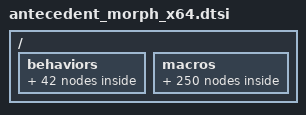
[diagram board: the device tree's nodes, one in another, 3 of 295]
// x64 schema version v1.1
// Automatically generated by Antecedent Morph Configurator

/ {
    behaviors {
        // Mod-Morphs
        // Base layer
        // NE
        amx64neagm: amx64neagm {
            compatible = "zmk,behavior-mod-morph";
            #binding-cells = <0>;
            bindings = <&amx64nea>, <&amx64neg>;
            mods = <(MOD_LGUI)>;
        };
        amx64necagm: amx64necagm {
            compatible = "zmk,behavior-mod-morph";
            #binding-cells = <0>;
            bindings = <&amx64nec>, <&amx64neagm>;
            mods = <(MOD_LALT|MOD_LGUI)>;
        };
        amx64nem: amx64nem {
            compatible = "zmk,behavior-mod-morph";
            #binding-cells = <0>;
            bindings = <&amx64ne>, <&amx64necagm>;
            mods = <(MOD_LCTL|MOD_LALT|MOD_LGUI)>;
        };
        // E
        amx64eagm: amx64eagm {
            compatible = "zmk,behavior-mod-morph";
            #binding-cells = <0>;
            bindings = <&amx64ea>, <&amx64eg>;
            mods = <(MOD_LGUI)>;
        };
        amx64ecagm: amx64ecagm {
            compatible = "zmk,behavior-mod-morph";
            #binding-cells = <0>;
            bindings = <&amx64ec>, <&amx64eagm>;
            mods = <(MOD_LALT|MOD_LGUI)>;
        };
        amx64em: amx64em {
            compatible = "zmk,behavior-mod-morph";
            #binding-cells = <0>;
            bindings = <&amx64e>, <&amx64ecagm>;
            mods = <(MOD_LCTL|MOD_LALT|MOD_LGUI)>;
        };
        // SE
        amx64seagm: amx64seagm {
            compatible = "zmk,behavior-mod-morph";
            #binding-cells = <0>;
            bindings = <&amx64sea>, <&amx64seg>;
            mods = <(MOD_LGUI)>;
        };
        amx64secagm: amx64secagm {
            compatible = "zmk,behavior-mod-morph";
            #binding-cells = <0>;
            bindings = <&amx64sec>, <&amx64seagm>;
            mods = <(MOD_LALT|MOD_LGUI)>;
        };
        amx64sem: amx64sem {
            compatible = "zmk,behavior-mod-morph";
            #binding-cells = <0>;
            bindings = <&amx64se>, <&amx64secagm>;
            mods = <(MOD_LCTL|MOD_LALT|MOD_LGUI)>;
        };
        // NW
        amx64nwagm: amx64nwagm {
            compatible = "zmk,behavior-mod-morph";
            #binding-cells = <0>;
            bindings = <&amx64nwa>, <&amx64nwg>;
            mods = <(MOD_RGUI)>;
        };
        amx64nwcagm: amx64nwcagm {
            compatible = "zmk,behavior-mod-morph";
            #binding-cells = <0>;
            bindings = <&amx64nwc>, <&amx64nwagm>;
            mods = <(MOD_RALT|MOD_RGUI)>;
        };
        amx64nwm: amx64nwm {
            compatible = "zmk,behavior-mod-morph";
            #binding-cells = <0>;
            bindings = <&amx64nw>, <&amx64nwcagm>;
            mods = <(MOD_RCTL|MOD_RALT|MOD_RGUI)>;
        };
        // W
        amx64wagm: amx64wagm {
            compatible = "zmk,behavior-mod-morph";
            #binding-cells = <0>;
            bindings = <&amx64wa>, <&amx64wg>;
            mods = <(MOD_RGUI)>;
        };
        amx64wcagm: amx64wcagm {
            compatible = "zmk,behavior-mod-morph";
            #binding-cells = <0>;
            bindings = <&amx64wc>, <&amx64wagm>;
            mods = <(MOD_RALT|MOD_RGUI)>;
        };
        amx64wm: amx64wm {
            compatible = "zmk,behavior-mod-morph";
            #binding-cells = <0>;
            bindings = <&amx64w>, <&amx64wcagm>;
            mods = <(MOD_RCTL|MOD_RALT|MOD_RGUI)>;
        };
        // SW
        amx64swagm: amx64swagm {
            compatible = "zmk,behavior-mod-morph";
            #binding-cells = <0>;
            bindings = <&amx64swa>, <&amx64swg>;
            mods = <(MOD_RGUI)>;
        };
        amx64swcagm: amx64swcagm {
            compatible = "zmk,behavior-mod-morph";
            #binding-cells = <0>;
            bindings = <&amx64swc>, <&amx64swagm>;
            mods = <(MOD_RALT|MOD_RGUI)>;
        };
        amx64swm: amx64swm {
            compatible = "zmk,behavior-mod-morph";
            #binding-cells = <0>;
            bindings = <&amx64sw>, <&amx64swcagm>;
            mods = <(MOD_RCTL|MOD_RALT|MOD_RGUI)>;
        };
        // Antecedent Morphs
        amx64ne: am_x64_ne {
            compatible = "zmk,behavior-antecedent-morph";
            label = "AM_X64_NE";
            #binding-cells = <0>;
            defaults = <&none>;
            bindings = <&amx64_and>, <&amx64_byte>, <&amx64_cmp>, <&amx64_dword>, <&amx64_rsi_rsi>, <&amx64_ja>, <&amx64_pop>, <&amx64_qword>, <&amx64_repe_cmps>, <&amx64_section>, <&amx64_0123456789>, <&amx64_word>, <&amx64_xor>, <&amx64_ymm0>, <&amx64_ymm1>, <&amx64_ymm2>, <&amx64_ymm3>, <&amx64_ymm4>, <&amx64_ymm5>, <&amx64_ymm6>, <&amx64_ymm7>, <&amx64_ymm8>, <&amx64_ymm9>, <&amx64_macro>;
            antecedents = <A B C D I J P Q R S T W X N0 N1 N2 N3 N4 N5 N6 N7 N8 N9 PRCNT>;
            max-delay-ms = <U_ANTMORPH_DELAY>;
        };
        amx64nec: am_x64_ne_c {
            compatible = "zmk,behavior-antecedent-morph";
            label = "AM_X64_NE_C";
            #binding-cells = <0>;
            defaults = <&none>;
            bindings = <&amx64_cmps>, <&amx64_jae>, <&amx64_repz_cmps>, <&amx64_section_data>, <&amx64_1234567890>, <&amx64_ymm0_ymm0>, <&amx64_ymm1_ymm1>, <&amx64_ymm2_ymm2>, <&amx64_ymm3_ymm3>, <&amx64_ymm4_ymm4>, <&amx64_ymm5_ymm5>, <&amx64_ymm6_ymm6>, <&amx64_ymm7_ymm7>, <&amx64_ymm8_ymm8>, <&amx64_ymm9_ymm9>, <&amx64_unmacro>;
            antecedents = <C J R S T N0 N1 N2 N3 N4 N5 N6 N7 N8 N9 PRCNT>;
            max-delay-ms = <U_ANTMORPH_DELAY>;
        };
        amx64nea: am_x64_ne_a {
            compatible = "zmk,behavior-antecedent-morph";
            label = "AM_X64_NE_A";
            #binding-cells = <0>;
            defaults = <&none>;
            bindings = <&amx64_jna>, <&amx64_repne_cmps>, <&amx64_section_text>;
            antecedents = <J R S>;
            max-delay-ms = <U_ANTMORPH_DELAY>;
        };
        amx64neg: am_x64_ne_g {
            compatible = "zmk,behavior-antecedent-morph";
            label = "AM_X64_NE_G";
            #binding-cells = <0>;
            defaults = <&none>;
            bindings = <&amx64_jnae>, <&amx64_repnz_cmps>, <&amx64_section_bss>, <&amx64_xor_rax_rax>;
            antecedents = <J R S X>;
            max-delay-ms = <U_ANTMORPH_DELAY>;
        };
        amx64e: am_x64_e {
            compatible = "zmk,behavior-antecedent-morph";
            label = "AM_X64_E";
            #binding-cells = <0>;
            defaults = <&none>;
            bindings = <&amx64_add>, <&amx64_bts>, <&amx64_call>, <&amx64_dec>, <&amx64_global>, <&amx64_rdi_rdi>, <&amx64_jmp>, <&amx64_lea>, <&amx64_mul>, <&amx64_push>, <&amx64_rep_stos>, <&amx64_sub>, <&amx64_test>, <&amx64_xorpd>, <&amx64_xmm0>, <&amx64_xmm1>, <&amx64_xmm2>, <&amx64_xmm3>, <&amx64_xmm4>, <&amx64_xmm5>, <&amx64_xmm6>, <&amx64_xmm7>, <&amx64_xmm8>, <&amx64_xmm9>, <&kp MINUS>, <&amx64_define>, <&amx64_rep>, <&amx64_assign>, <&amx64_x64_v11>;
            antecedents = <A B C D G I J L M P R S T X N0 N1 N2 N3 N4 N5 N6 N7 N8 N9 DLLR PRCNT AT EQUAL SPACE>;
            max-delay-ms = <U_ANTMORPH_DELAY>;
        };
        amx64ec: am_x64_e_c {
            compatible = "zmk,behavior-antecedent-morph";
            label = "AM_X64_E_C";
            #binding-cells = <0>;
            defaults = <&none>;
            bindings = <&amx64_addsd>, <&amx64_call_printf>, <&amx64_global_main>, <&amx64_jc>, <&amx64_mulsd>, <&amx64_rep_movs>, <&amx64_subsd>, <&amx64_xorps>, <&amx64_xmm0_xmm0>, <&amx64_xmm1_xmm1>, <&amx64_xmm2_xmm2>, <&amx64_xmm3_xmm3>, <&amx64_xmm4_xmm4>, <&amx64_xmm5_xmm5>, <&amx64_xmm6_xmm6>, <&amx64_xmm7_xmm7>, <&amx64_xmm8_xmm8>, <&amx64_xmm9_xmm9>, <&amx64_undef>, <&amx64_exitrep>;
            antecedents = <A C G J M R S X N0 N1 N2 N3 N4 N5 N6 N7 N8 N9 PRCNT AT>;
            max-delay-ms = <U_ANTMORPH_DELAY>;
        };
        amx64ea: am_x64_e_a {
            compatible = "zmk,behavior-antecedent-morph";
            label = "AM_X64_E_A";
            #binding-cells = <0>;
            defaults = <&none>;
            bindings = <&amx64_addss>, <&amx64_global_start>, <&amx64_jnc>, <&amx64_mulss>, <&amx64_subss>, <&amx64_xdefine>;
            antecedents = <A G J M S PRCNT>;
            max-delay-ms = <U_ANTMORPH_DELAY>;
        };
        amx64eg: am_x64_e_g {
            compatible = "zmk,behavior-antecedent-morph";
            label = "AM_X64_E_G";
            #binding-cells = <0>;
            defaults = <&none>;
            bindings = <&none>;
            antecedents = <0x070100>;
            max-delay-ms = <U_ANTMORPH_DELAY>;
        };
        amx64se: am_x64_se {
            compatible = "zmk,behavior-antecedent-morph";
            label = "AM_X64_SE";
            #binding-cells = <0>;
            defaults = <&none>;
            bindings = <&amx64_btr>, <&amx64_cvtss2sd>, <&amx64_db>, <&amx64_equ>, <&amx64_jb>, <&amx64_movdbu>, <&amx64_pextrb>, <&amx64_resb>, <&amx64_syscall>, <&amx64_0123456789abcde>, <&amx64_vextractf128>, <&amx64_pxor>, <&amx64_00000000>, <&amx64_11111111>, <&amx64_endmacro>, <&amx64_endrep>;
            antecedents = <B C D E J M P R S T V X N0 N1 PRCNT AT>;
            max-delay-ms = <U_ANTMORPH_DELAY>;
        };
        amx64sec: am_x64_se_c {
            compatible = "zmk,behavior-antecedent-morph";
            label = "AM_X64_SE_C";
            #binding-cells = <0>;
            defaults = <&none>;
            bindings = <&amx64_cvtsd2ss>, <&amx64_dw>, <&amx64_equ__>, <&amx64_jbe>, <&amx64_movdwu>, <&amx64_pextrw>, <&amx64_resw>, <&amx64_123456789abcdef>, <&amx64_vextracti128>, <&amx64_000000000000000>, <&amx64_111111111111111>;
            antecedents = <C D E J M P R T V N0 N1>;
            max-delay-ms = <U_ANTMORPH_DELAY>;
        };
        amx64sea: am_x64_se_a {
            compatible = "zmk,behavior-antecedent-morph";
            label = "AM_X64_SE_A";
            #binding-cells = <0>;
            defaults = <&none>;
            bindings = <&amx64_dd>, <&amx64_jnb>, <&amx64_movddu>, <&amx64_pextrd>, <&amx64_resd>, <&amx64_0000000000000001>, <&amx64_1111111111111111>;
            antecedents = <D J M P R N0 N1>;
            max-delay-ms = <U_ANTMORPH_DELAY>;
        };
        amx64seg: am_x64_se_g {
            compatible = "zmk,behavior-antecedent-morph";
            label = "AM_X64_SE_G";
            #binding-cells = <0>;
            defaults = <&none>;
            bindings = <&amx64_dq>, <&amx64_jnbe>, <&amx64_movdqu>, <&amx64_pextrq>, <&amx64_resq>, <&amx64_pxor_xmm0_xmm0>, <&amx64_0000000000000002>, <&amx64_1111111111111112>;
            antecedents = <D J M P R X N0 N1>;
            max-delay-ms = <U_ANTMORPH_DELAY>;
        };
        amx64nw: am_x64_nw {
            compatible = "zmk,behavior-antecedent-morph";
            label = "AM_X64_NW";
            #binding-cells = <0>;
            defaults = <&none>;
            bindings = <&amx64_rax_rax>, <&amx64_rbx_rbx>, <&amx64_rcx_rcx>, <&amx64_rdx_rdx>, <&amx64_extern>, <&amx64_imul>, <&amx64_jg>, <&amx64_loop>, <&amx64_movapd>, <&amx64_not>, <&amx64_or>, <&amx64_rsp_rsp>, <&amx64_repe_scas>, <&amx64_sar>, <&amx64_times>, <&amx64_vmovapd>, <&amx64_r10_r10>, <&amx64_r11_r11>, <&amx64_r12_r12>, <&amx64_r13_r13>, <&amx64_r14_r14>, <&amx64_r15_r15>, <&amx64_r8_r8>, <&amx64_r9_r9>, <&amx64_100>, <&amx64_1001>, <&amx64_include>;
            antecedents = <A B C D E I J L M N O P R S T V N0 N1 N2 N3 N4 N5 N8 N9 COMMA SQT PRCNT>;
            max-delay-ms = <U_ANTMORPH_DELAY>;
        };
        amx64nwc: am_x64_nw_c {
            compatible = "zmk,behavior-antecedent-morph";
            label = "AM_X64_NW_C";
            #binding-cells = <0>;
            defaults = <&none>;
            bindings = <&amx64_extern_printf>, <&amx64_jge>, <&amx64_loop_loop>, <&amx64_movaps>, <&amx64_repz_scas>, <&amx64_shr>, <&amx64_vmovaps>, <&amx64_10100>, <&amx64_101001>;
            antecedents = <E J L M R S V COMMA SQT>;
            max-delay-ms = <U_ANTMORPH_DELAY>;
        };
        amx64nwa: am_x64_nw_a {
            compatible = "zmk,behavior-antecedent-morph";
            label = "AM_X64_NW_A";
            #binding-cells = <0>;
            defaults = <&none>;
            bindings = <&amx64_jng>, <&amx64_movupd>, <&amx64_repne_scas>, <&amx64_vmovupd>;
            antecedents = <J M R V>;
            max-delay-ms = <U_ANTMORPH_DELAY>;
        };
        amx64nwg: am_x64_nw_g {
            compatible = "zmk,behavior-antecedent-morph";
            label = "AM_X64_NW_G";
            #binding-cells = <0>;
            defaults = <&none>;
            bindings = <&amx64_jnge>, <&amx64_movups>, <&amx64_repnz_scas>, <&amx64_vmovups>;
            antecedents = <J M R V>;
            max-delay-ms = <U_ANTMORPH_DELAY>;
        };
        amx64w: am_x64_w {
            compatible = "zmk,behavior-antecedent-morph";
            label = "AM_X64_W";
            #binding-cells = <0>;
            defaults = <&none>;
            bindings = <&amx64_align>, <&amx64_bt>, <&amx64_cpuid>, <&amx64_div>, <&amx64_enter_0_0>, <&amx64_inc>, <&amx64_je>, <&amx64_leave>, <&amx64_mov>, <&amx64_neg>, <&amx64_rbp_rbp>, <&amx64_rol>, <&amx64_sal>, <&amx64_76543210>, <&amx64_vzeroall>, <&amx64_vxorpd>, <&amx64_0xff>, <&kp N0>, <&amx64_0>, <&amx64_if>;
            antecedents = <A B C D E I J L M N P R S T V X N0 COMMA SQT PRCNT>;
            max-delay-ms = <U_ANTMORPH_DELAY>;
        };
        amx64wc: am_x64_w_c {
            compatible = "zmk,behavior-antecedent-morph";
            label = "AM_X64_W_C";
            #binding-cells = <0>;
            defaults = <&none>;
            bindings = <&amx64_alignb>, <&amx64_divsd>, <&amx64_push_rbpmov_rbp>, <&amx64_jz>, <&amx64_mov_rsp_rbppop_>, <&amx64_movsd>, <&amx64_ror>, <&amx64_shl>, <&amx64_1__0>, <&amx64_vxorps>, <&amx64_0xffff>, <&amx64_elif>;
            antecedents = <A D E J L M R S T X N0 PRCNT>;
            max-delay-ms = <U_ANTMORPH_DELAY>;
        };
        amx64wa: am_x64_w_a {
            compatible = "zmk,behavior-antecedent-morph";
            label = "AM_X64_W_A";
            #binding-cells = <0>;
            defaults = <&none>;
            bindings = <&amx64_divss>, <&amx64_jne>, <&amx64_movss>, <&amx64_3__2__1__0>, <&amx64_0xffffffff>, <&amx64_else>;
            antecedents = <D J M T N0 PRCNT>;
            max-delay-ms = <U_ANTMORPH_DELAY>;
        };
        amx64wg: am_x64_w_g {
            compatible = "zmk,behavior-antecedent-morph";
            label = "AM_X64_W_G";
            #binding-cells = <0>;
            defaults = <&none>;
            bindings = <&amx64_jnz>, <&amx64_6__5__4__3__2__>, <&amx64_0xfffffffffffff>;
            antecedents = <J T N0>;
            max-delay-ms = <U_ANTMORPH_DELAY>;
        };
        amx64sw: am_x64_sw {
            compatible = "zmk,behavior-antecedent-morph";
            label = "AM_X64_SW";
            #binding-cells = <0>;
            defaults = <&none>;
            bindings = <&amx64_extractpd>, <&amx64_idiv>, <&amx64_jl>, <&amx64_movdba>, <&amx64_pinsrb>, <&amx64_sqrtsd>, <&amx64_vinsertf128>, <&amx64_0x00>, <&kp N9>, <&amx64_9>, <&amx64_endif>;
            antecedents = <E I J M P S V N0 COMMA SQT PRCNT>;
            max-delay-ms = <U_ANTMORPH_DELAY>;
        };
        amx64swc: am_x64_sw_c {
            compatible = "zmk,behavior-antecedent-morph";
            label = "AM_X64_SW_C";
            #binding-cells = <0>;
            defaults = <&none>;
            bindings = <&amx64_jle>, <&amx64_movdwa>, <&amx64_pinsrw>, <&amx64_vinserti128>, <&amx64_0x0000>;
            antecedents = <J M P V N0>;
            max-delay-ms = <U_ANTMORPH_DELAY>;
        };
        amx64swa: am_x64_sw_a {
            compatible = "zmk,behavior-antecedent-morph";
            label = "AM_X64_SW_A";
            #binding-cells = <0>;
            defaults = <&none>;
            bindings = <&amx64_jnl>, <&amx64_movdda>, <&amx64_pinsrd>, <&amx64_0x00000000>;
            antecedents = <J M P N0>;
            max-delay-ms = <U_ANTMORPH_DELAY>;
        };
        amx64swg: am_x64_sw_g {
            compatible = "zmk,behavior-antecedent-morph";
            label = "AM_X64_SW_G";
            #binding-cells = <0>;
            defaults = <&none>;
            bindings = <&amx64_jnle>, <&amx64_movdqa>, <&amx64_pinsrq>, <&amx64_0x0000000000000>;
            antecedents = <J M P N0>;
            max-delay-ms = <U_ANTMORPH_DELAY>;
        };
    };
    macros {
        // 'A'
        amx64_and: amx64_and {
            compatible = "zmk,behavior-macro";
            #binding-cells = <0>;
            wait-ms = <U_ANTMORPH_MACRO_WAIT>;
            tap-ms = <U_ANTMORPH_MACRO_TAP>;
            // (a)nd     
            bindings = <&macro_tap &kp N &kp D &kp SPACE &kp SPACE &kp SPACE &kp SPACE &kp SPACE>;
        };
        amx64_add: amx64_add {
            compatible = "zmk,behavior-macro";
            #binding-cells = <0>;
            wait-ms = <U_ANTMORPH_MACRO_WAIT>;
            tap-ms = <U_ANTMORPH_MACRO_TAP>;
            // (a)dd     
            bindings = <&macro_tap &kp D &kp D &kp SPACE &kp SPACE &kp SPACE &kp SPACE &kp SPACE>;
        };
        amx64_addsd: amx64_addsd {
            compatible = "zmk,behavior-macro";
            #binding-cells = <0>;
            wait-ms = <U_ANTMORPH_MACRO_WAIT>;
            tap-ms = <U_ANTMORPH_MACRO_TAP>;
            // (a)ddsd   
            bindings = <&macro_release &kp LCTRL>, <&macro_tap &kp D &kp D &kp S &kp D &kp SPACE &kp SPACE &kp SPACE>;
        };
        amx64_addss: amx64_addss {
            compatible = "zmk,behavior-macro";
            #binding-cells = <0>;
            wait-ms = <U_ANTMORPH_MACRO_WAIT>;
            tap-ms = <U_ANTMORPH_MACRO_TAP>;
            // (a)ddss   
            bindings = <&macro_release &kp LALT>, <&macro_tap &kp LALT>, <&macro_tap &kp D &kp D &kp S &kp S &kp SPACE &kp SPACE &kp SPACE>;
        };
        amx64_rax_rax: amx64_rax_rax {
            compatible = "zmk,behavior-macro";
            #binding-cells = <0>;
            wait-ms = <U_ANTMORPH_MACRO_WAIT>;
            tap-ms = <U_ANTMORPH_MACRO_TAP>;
            // [a]rax, rax
            bindings = <&macro_tap &kp BSPC &kp R &kp A &kp X &kp COMMA &kp SPACE &kp R &kp A &kp X>;
        };
        amx64_align: amx64_align {
            compatible = "zmk,behavior-macro";
            #binding-cells = <0>;
            wait-ms = <U_ANTMORPH_MACRO_WAIT>;
            tap-ms = <U_ANTMORPH_MACRO_TAP>;
            // (a)lign 
            bindings = <&macro_tap &kp L &kp I &kp G &kp N &kp SPACE>;
        };
        amx64_alignb: amx64_alignb {
            compatible = "zmk,behavior-macro";
            #binding-cells = <0>;
            wait-ms = <U_ANTMORPH_MACRO_WAIT>;
            tap-ms = <U_ANTMORPH_MACRO_TAP>;
            // (a)lignb 
            bindings = <&macro_release &kp RCTRL>, <&macro_tap &kp L &kp I &kp G &kp N &kp B &kp SPACE>;
        };
        // 'B'
        amx64_byte: amx64_byte {
            compatible = "zmk,behavior-macro";
            #binding-cells = <0>;
            wait-ms = <U_ANTMORPH_MACRO_WAIT>;
            tap-ms = <U_ANTMORPH_MACRO_TAP>;
            // (b)yte
            bindings = <&macro_tap &kp Y &kp T &kp E>;
        };
        amx64_bts: amx64_bts {
            compatible = "zmk,behavior-macro";
            #binding-cells = <0>;
            wait-ms = <U_ANTMORPH_MACRO_WAIT>;
            tap-ms = <U_ANTMORPH_MACRO_TAP>;
            // (b)ts     
            bindings = <&macro_tap &kp T &kp S &kp SPACE &kp SPACE &kp SPACE &kp SPACE &kp SPACE>;
        };
        amx64_btr: amx64_btr {
            compatible = "zmk,behavior-macro";
            #binding-cells = <0>;
            wait-ms = <U_ANTMORPH_MACRO_WAIT>;
            tap-ms = <U_ANTMORPH_MACRO_TAP>;
            // (b)tr     
            bindings = <&macro_tap &kp T &kp R &kp SPACE &kp SPACE &kp SPACE &kp SPACE &kp SPACE>;
        };
        amx64_rbx_rbx: amx64_rbx_rbx {
            compatible = "zmk,behavior-macro";
            #binding-cells = <0>;
            wait-ms = <U_ANTMORPH_MACRO_WAIT>;
            tap-ms = <U_ANTMORPH_MACRO_TAP>;
            // [b]rbx, rbx
            bindings = <&macro_tap &kp BSPC &kp R &kp B &kp X &kp COMMA &kp SPACE &kp R &kp B &kp X>;
        };
        amx64_bt: amx64_bt {
            compatible = "zmk,behavior-macro";
            #binding-cells = <0>;
            wait-ms = <U_ANTMORPH_MACRO_WAIT>;
            tap-ms = <U_ANTMORPH_MACRO_TAP>;
            // (b)t      
            bindings = <&macro_tap &kp T &kp SPACE &kp SPACE &kp SPACE &kp SPACE &kp SPACE &kp SPACE>;
        };
        // 'C'
        amx64_cmp: amx64_cmp {
            compatible = "zmk,behavior-macro";
            #binding-cells = <0>;
            wait-ms = <U_ANTMORPH_MACRO_WAIT>;
            tap-ms = <U_ANTMORPH_MACRO_TAP>;
            // (c)mp     
            bindings = <&macro_tap &kp M &kp P &kp SPACE &kp SPACE &kp SPACE &kp SPACE &kp SPACE>;
        };
        amx64_cmps: amx64_cmps {
            compatible = "zmk,behavior-macro";
            #binding-cells = <0>;
            wait-ms = <U_ANTMORPH_MACRO_WAIT>;
            tap-ms = <U_ANTMORPH_MACRO_TAP>;
            // (c)mps
            bindings = <&macro_release &kp LCTRL>, <&macro_tap &kp M &kp P &kp S>;
        };
        amx64_call: amx64_call {
            compatible = "zmk,behavior-macro";
            #binding-cells = <0>;
            wait-ms = <U_ANTMORPH_MACRO_WAIT>;
            tap-ms = <U_ANTMORPH_MACRO_TAP>;
            // (c)all    
            bindings = <&macro_tap &kp A &kp L &kp L &kp SPACE &kp SPACE &kp SPACE &kp SPACE>;
        };
        amx64_call_printf: amx64_call_printf {
            compatible = "zmk,behavior-macro";
            #binding-cells = <0>;
            wait-ms = <U_ANTMORPH_MACRO_WAIT>;
            tap-ms = <U_ANTMORPH_MACRO_TAP>;
            // (c)all    printf
            bindings = <&macro_release &kp LCTRL>, <&macro_tap &kp A &kp L &kp L &kp SPACE &kp SPACE &kp SPACE &kp SPACE &kp P &kp R &kp I &kp N &kp T &kp F>;
        };
        amx64_cvtss2sd: amx64_cvtss2sd {
            compatible = "zmk,behavior-macro";
            #binding-cells = <0>;
            wait-ms = <U_ANTMORPH_MACRO_WAIT>;
            tap-ms = <U_ANTMORPH_MACRO_TAP>;
            // (c)vtss2sd 
            bindings = <&macro_tap &kp V &kp T &kp S &kp S &kp N2 &kp S &kp D &kp SPACE>;
        };
        amx64_cvtsd2ss: amx64_cvtsd2ss {
            compatible = "zmk,behavior-macro";
            #binding-cells = <0>;
            wait-ms = <U_ANTMORPH_MACRO_WAIT>;
            tap-ms = <U_ANTMORPH_MACRO_TAP>;
            // (c)vtsd2ss 
            bindings = <&macro_release &kp LCTRL>, <&macro_tap &kp V &kp T &kp S &kp D &kp N2 &kp S &kp S &kp SPACE>;
        };
        amx64_rcx_rcx: amx64_rcx_rcx {
            compatible = "zmk,behavior-macro";
            #binding-cells = <0>;
            wait-ms = <U_ANTMORPH_MACRO_WAIT>;
            tap-ms = <U_ANTMORPH_MACRO_TAP>;
            // [c]rcx, rcx
            bindings = <&macro_tap &kp BSPC &kp R &kp C &kp X &kp COMMA &kp SPACE &kp R &kp C &kp X>;
        };
        amx64_cpuid: amx64_cpuid {
            compatible = "zmk,behavior-macro";
            #binding-cells = <0>;
            wait-ms = <U_ANTMORPH_MACRO_WAIT>;
            tap-ms = <U_ANTMORPH_MACRO_TAP>;
            // (c)puid
            bindings = <&macro_tap &kp P &kp U &kp I &kp D>;
        };
        // 'D'
        amx64_dword: amx64_dword {
            compatible = "zmk,behavior-macro";
            #binding-cells = <0>;
            wait-ms = <U_ANTMORPH_MACRO_WAIT>;
            tap-ms = <U_ANTMORPH_MACRO_TAP>;
            // (d)word
            bindings = <&macro_tap &kp W &kp O &kp R &kp D>;
        };
        amx64_dec: amx64_dec {
            compatible = "zmk,behavior-macro";
            #binding-cells = <0>;
            wait-ms = <U_ANTMORPH_MACRO_WAIT>;
            tap-ms = <U_ANTMORPH_MACRO_TAP>;
            // (d)ec     
            bindings = <&macro_tap &kp E &kp C &kp SPACE &kp SPACE &kp SPACE &kp SPACE &kp SPACE>;
        };
        amx64_db: amx64_db {
            compatible = "zmk,behavior-macro";
            #binding-cells = <0>;
            wait-ms = <U_ANTMORPH_MACRO_WAIT>;
            tap-ms = <U_ANTMORPH_MACRO_TAP>;
            // (d)b   
            bindings = <&macro_tap &kp B &kp SPACE &kp SPACE &kp SPACE>;
        };
        amx64_dw: amx64_dw {
            compatible = "zmk,behavior-macro";
            #binding-cells = <0>;
            wait-ms = <U_ANTMORPH_MACRO_WAIT>;
            tap-ms = <U_ANTMORPH_MACRO_TAP>;
            // (d)w   
            bindings = <&macro_release &kp LCTRL>, <&macro_tap &kp W &kp SPACE &kp SPACE &kp SPACE>;
        };
        amx64_dd: amx64_dd {
            compatible = "zmk,behavior-macro";
            #binding-cells = <0>;
            wait-ms = <U_ANTMORPH_MACRO_WAIT>;
            tap-ms = <U_ANTMORPH_MACRO_TAP>;
            // (d)d   
            bindings = <&macro_release &kp LALT>, <&macro_tap &kp LALT>, <&macro_tap &kp D &kp SPACE &kp SPACE &kp SPACE>;
        };
        amx64_dq: amx64_dq {
            compatible = "zmk,behavior-macro";
            #binding-cells = <0>;
            wait-ms = <U_ANTMORPH_MACRO_WAIT>;
            tap-ms = <U_ANTMORPH_MACRO_TAP>;
            // (d)q   
            bindings = <&macro_release &kp LGUI>, <&macro_tap &kp LGUI>, <&macro_tap &kp Q &kp SPACE &kp SPACE &kp SPACE>;
        };
        amx64_rdx_rdx: amx64_rdx_rdx {
            compatible = "zmk,behavior-macro";
            #binding-cells = <0>;
            wait-ms = <U_ANTMORPH_MACRO_WAIT>;
            tap-ms = <U_ANTMORPH_MACRO_TAP>;
            // [d]rdx, rdx
            bindings = <&macro_tap &kp BSPC &kp R &kp D &kp X &kp COMMA &kp SPACE &kp R &kp D &kp X>;
        };
        amx64_div: amx64_div {
            compatible = "zmk,behavior-macro";
            #binding-cells = <0>;
            wait-ms = <U_ANTMORPH_MACRO_WAIT>;
            tap-ms = <U_ANTMORPH_MACRO_TAP>;
            // (d)iv     
            bindings = <&macro_tap &kp I &kp V &kp SPACE &kp SPACE &kp SPACE &kp SPACE &kp SPACE>;
        };
        amx64_divsd: amx64_divsd {
            compatible = "zmk,behavior-macro";
            #binding-cells = <0>;
            wait-ms = <U_ANTMORPH_MACRO_WAIT>;
            tap-ms = <U_ANTMORPH_MACRO_TAP>;
            // (d)ivsd   
            bindings = <&macro_release &kp RCTRL>, <&macro_tap &kp I &kp V &kp S &kp D &kp SPACE &kp SPACE &kp SPACE>;
        };
        amx64_divss: amx64_divss {
            compatible = "zmk,behavior-macro";
            #binding-cells = <0>;
            wait-ms = <U_ANTMORPH_MACRO_WAIT>;
            tap-ms = <U_ANTMORPH_MACRO_TAP>;
            // (d)ivss   
            bindings = <&macro_release &kp RALT>, <&macro_tap &kp RALT>, <&macro_tap &kp I &kp V &kp S &kp S &kp SPACE &kp SPACE &kp SPACE>;
        };
        // 'E'
        amx64_equ: amx64_equ {
            compatible = "zmk,behavior-macro";
            #binding-cells = <0>;
            wait-ms = <U_ANTMORPH_MACRO_WAIT>;
            tap-ms = <U_ANTMORPH_MACRO_TAP>;
            // (e)qu  
            bindings = <&macro_tap &kp Q &kp U &kp SPACE &kp SPACE>;
        };
        amx64_equ__: amx64_equ__ {
            compatible = "zmk,behavior-macro";
            #binding-cells = <0>;
            wait-ms = <U_ANTMORPH_MACRO_WAIT>;
            tap-ms = <U_ANTMORPH_MACRO_TAP>;
            // (e)qu  $-
            bindings = <&macro_release &kp LCTRL>, <&macro_tap &kp Q &kp U &kp SPACE &kp SPACE &kp DLLR &kp MINUS>;
        };
        amx64_extern: amx64_extern {
            compatible = "zmk,behavior-macro";
            #binding-cells = <0>;
            wait-ms = <U_ANTMORPH_MACRO_WAIT>;
            tap-ms = <U_ANTMORPH_MACRO_TAP>;
            // (e)xtern 
            bindings = <&macro_tap &kp X &kp T &kp E &kp R &kp N &kp SPACE>;
        };
        amx64_extern_printf: amx64_extern_printf {
            compatible = "zmk,behavior-macro";
            #binding-cells = <0>;
            wait-ms = <U_ANTMORPH_MACRO_WAIT>;
            tap-ms = <U_ANTMORPH_MACRO_TAP>;
            // (e)xtern printf
            bindings = <&macro_release &kp RCTRL>, <&macro_tap &kp X &kp T &kp E &kp R &kp N &kp SPACE &kp P &kp R &kp I &kp N &kp T &kp F>;
        };
        amx64_enter_0_0: amx64_enter_0_0 {
            compatible = "zmk,behavior-macro";
            #binding-cells = <0>;
            wait-ms = <U_ANTMORPH_MACRO_WAIT>;
            tap-ms = <U_ANTMORPH_MACRO_TAP>;
            // (e)nter   0, 0
            bindings = <&macro_tap &kp N &kp T &kp E &kp R &kp SPACE &kp SPACE &kp SPACE &kp N0 &kp COMMA &kp SPACE &kp N0>;
        };
        amx64_push_rbpmov_rbp: amx64_push_rbpmov_rbp {
            compatible = "zmk,behavior-macro";
            #binding-cells = <0>;
            wait-ms = <U_ANTMORPH_MACRO_WAIT>;
            tap-ms = <U_ANTMORPH_MACRO_TAP>;
            // [e]push    rbp⏎mov     rbp, rsp
            bindings = <&macro_release &kp RCTRL>, <&macro_tap &kp BSPC &kp P &kp U &kp S &kp H &kp SPACE &kp SPACE &kp SPACE &kp SPACE &kp R &kp B &kp P &kp RET &kp M &kp O &kp V &kp SPACE &kp SPACE &kp SPACE &kp SPACE &kp SPACE &kp R &kp B &kp P &kp COMMA &kp SPACE &kp R &kp S &kp P>;
        };
        amx64_extractpd: amx64_extractpd {
            compatible = "zmk,behavior-macro";
            #binding-cells = <0>;
            wait-ms = <U_ANTMORPH_MACRO_WAIT>;
            tap-ms = <U_ANTMORPH_MACRO_TAP>;
            // (e)xtractpd 
            bindings = <&macro_tap &kp X &kp T &kp R &kp A &kp C &kp T &kp P &kp D &kp SPACE>;
        };
        // 'G'
        amx64_global: amx64_global {
            compatible = "zmk,behavior-macro";
            #binding-cells = <0>;
            wait-ms = <U_ANTMORPH_MACRO_WAIT>;
            tap-ms = <U_ANTMORPH_MACRO_TAP>;
            // (g)lobal 
            bindings = <&macro_tap &kp L &kp O &kp B &kp A &kp L &kp SPACE>;
        };
        amx64_global_main: amx64_global_main {
            compatible = "zmk,behavior-macro";
            #binding-cells = <0>;
            wait-ms = <U_ANTMORPH_MACRO_WAIT>;
            tap-ms = <U_ANTMORPH_MACRO_TAP>;
            // (g)lobal main
            bindings = <&macro_release &kp LCTRL>, <&macro_tap &kp L &kp O &kp B &kp A &kp L &kp SPACE &kp M &kp A &kp I &kp N>;
        };
        amx64_global_start: amx64_global_start {
            compatible = "zmk,behavior-macro";
            #binding-cells = <0>;
            wait-ms = <U_ANTMORPH_MACRO_WAIT>;
            tap-ms = <U_ANTMORPH_MACRO_TAP>;
            // (g)lobal _start
            bindings = <&macro_release &kp LALT>, <&macro_tap &kp LALT>, <&macro_tap &kp L &kp O &kp B &kp A &kp L &kp SPACE &kp UNDER &kp S &kp T &kp A &kp R &kp T>;
        };
        // 'I'
        amx64_rsi_rsi: amx64_rsi_rsi {
            compatible = "zmk,behavior-macro";
            #binding-cells = <0>;
            wait-ms = <U_ANTMORPH_MACRO_WAIT>;
            tap-ms = <U_ANTMORPH_MACRO_TAP>;
            // [i]rsi, rsi
            bindings = <&macro_tap &kp BSPC &kp R &kp S &kp I &kp COMMA &kp SPACE &kp R &kp S &kp I>;
        };
        amx64_rdi_rdi: amx64_rdi_rdi {
            compatible = "zmk,behavior-macro";
            #binding-cells = <0>;
            wait-ms = <U_ANTMORPH_MACRO_WAIT>;
            tap-ms = <U_ANTMORPH_MACRO_TAP>;
            // [i]rdi, rdi
            bindings = <&macro_tap &kp BSPC &kp R &kp D &kp I &kp COMMA &kp SPACE &kp R &kp D &kp I>;
        };
        amx64_imul: amx64_imul {
            compatible = "zmk,behavior-macro";
            #binding-cells = <0>;
            wait-ms = <U_ANTMORPH_MACRO_WAIT>;
            tap-ms = <U_ANTMORPH_MACRO_TAP>;
            // (i)mul    
            bindings = <&macro_tap &kp M &kp U &kp L &kp SPACE &kp SPACE &kp SPACE &kp SPACE>;
        };
        amx64_inc: amx64_inc {
            compatible = "zmk,behavior-macro";
            #binding-cells = <0>;
            wait-ms = <U_ANTMORPH_MACRO_WAIT>;
            tap-ms = <U_ANTMORPH_MACRO_TAP>;
            // (i)nc     
            bindings = <&macro_tap &kp N &kp C &kp SPACE &kp SPACE &kp SPACE &kp SPACE &kp SPACE>;
        };
        amx64_idiv: amx64_idiv {
            compatible = "zmk,behavior-macro";
            #binding-cells = <0>;
            wait-ms = <U_ANTMORPH_MACRO_WAIT>;
            tap-ms = <U_ANTMORPH_MACRO_TAP>;
            // (i)div    
            bindings = <&macro_tap &kp D &kp I &kp V &kp SPACE &kp SPACE &kp SPACE &kp SPACE>;
        };
        // 'J'
        amx64_ja: amx64_ja {
            compatible = "zmk,behavior-macro";
            #binding-cells = <0>;
            wait-ms = <U_ANTMORPH_MACRO_WAIT>;
            tap-ms = <U_ANTMORPH_MACRO_TAP>;
            // (j)a      
            bindings = <&macro_tap &kp A &kp SPACE &kp SPACE &kp SPACE &kp SPACE &kp SPACE &kp SPACE>;
        };
        amx64_jae: amx64_jae {
            compatible = "zmk,behavior-macro";
            #binding-cells = <0>;
            wait-ms = <U_ANTMORPH_MACRO_WAIT>;
            tap-ms = <U_ANTMORPH_MACRO_TAP>;
            // (j)ae     
            bindings = <&macro_release &kp LCTRL>, <&macro_tap &kp A &kp E &kp SPACE &kp SPACE &kp SPACE &kp SPACE &kp SPACE>;
        };
        amx64_jna: amx64_jna {
            compatible = "zmk,behavior-macro";
            #binding-cells = <0>;
            wait-ms = <U_ANTMORPH_MACRO_WAIT>;
            tap-ms = <U_ANTMORPH_MACRO_TAP>;
            // (j)na     
            bindings = <&macro_release &kp LALT>, <&macro_tap &kp LALT>, <&macro_tap &kp N &kp A &kp SPACE &kp SPACE &kp SPACE &kp SPACE &kp SPACE>;
        };
        amx64_jnae: amx64_jnae {
            compatible = "zmk,behavior-macro";
            #binding-cells = <0>;
            wait-ms = <U_ANTMORPH_MACRO_WAIT>;
            tap-ms = <U_ANTMORPH_MACRO_TAP>;
            // (j)nae    
            bindings = <&macro_release &kp LGUI>, <&macro_tap &kp LGUI>, <&macro_tap &kp N &kp A &kp E &kp SPACE &kp SPACE &kp SPACE &kp SPACE>;
        };
        amx64_jmp: amx64_jmp {
            compatible = "zmk,behavior-macro";
            #binding-cells = <0>;
            wait-ms = <U_ANTMORPH_MACRO_WAIT>;
            tap-ms = <U_ANTMORPH_MACRO_TAP>;
            // (j)mp     
            bindings = <&macro_tap &kp M &kp P &kp SPACE &kp SPACE &kp SPACE &kp SPACE &kp SPACE>;
        };
        amx64_jc: amx64_jc {
            compatible = "zmk,behavior-macro";
            #binding-cells = <0>;
            wait-ms = <U_ANTMORPH_MACRO_WAIT>;
            tap-ms = <U_ANTMORPH_MACRO_TAP>;
            // (j)c      
            bindings = <&macro_release &kp LCTRL>, <&macro_tap &kp C &kp SPACE &kp SPACE &kp SPACE &kp SPACE &kp SPACE &kp SPACE>;
        };
        amx64_jnc: amx64_jnc {
            compatible = "zmk,behavior-macro";
            #binding-cells = <0>;
            wait-ms = <U_ANTMORPH_MACRO_WAIT>;
            tap-ms = <U_ANTMORPH_MACRO_TAP>;
            // (j)nc     
            bindings = <&macro_release &kp LALT>, <&macro_tap &kp LALT>, <&macro_tap &kp N &kp C &kp SPACE &kp SPACE &kp SPACE &kp SPACE &kp SPACE>;
        };
        amx64_jb: amx64_jb {
            compatible = "zmk,behavior-macro";
            #binding-cells = <0>;
            wait-ms = <U_ANTMORPH_MACRO_WAIT>;
            tap-ms = <U_ANTMORPH_MACRO_TAP>;
            // (j)b      
            bindings = <&macro_tap &kp B &kp SPACE &kp SPACE &kp SPACE &kp SPACE &kp SPACE &kp SPACE>;
        };
        amx64_jbe: amx64_jbe {
            compatible = "zmk,behavior-macro";
            #binding-cells = <0>;
            wait-ms = <U_ANTMORPH_MACRO_WAIT>;
            tap-ms = <U_ANTMORPH_MACRO_TAP>;
            // (j)be     
            bindings = <&macro_release &kp LCTRL>, <&macro_tap &kp B &kp E &kp SPACE &kp SPACE &kp SPACE &kp SPACE &kp SPACE>;
        };
        amx64_jnb: amx64_jnb {
            compatible = "zmk,behavior-macro";
            #binding-cells = <0>;
            wait-ms = <U_ANTMORPH_MACRO_WAIT>;
            tap-ms = <U_ANTMORPH_MACRO_TAP>;
            // (j)nb     
            bindings = <&macro_release &kp LALT>, <&macro_tap &kp LALT>, <&macro_tap &kp N &kp B &kp SPACE &kp SPACE &kp SPACE &kp SPACE &kp SPACE>;
        };
        amx64_jnbe: amx64_jnbe {
            compatible = "zmk,behavior-macro";
            #binding-cells = <0>;
            wait-ms = <U_ANTMORPH_MACRO_WAIT>;
            tap-ms = <U_ANTMORPH_MACRO_TAP>;
            // (j)nbe    
            bindings = <&macro_release &kp LGUI>, <&macro_tap &kp LGUI>, <&macro_tap &kp N &kp B &kp E &kp SPACE &kp SPACE &kp SPACE &kp SPACE>;
        };
        amx64_jg: amx64_jg {
            compatible = "zmk,behavior-macro";
            #binding-cells = <0>;
            wait-ms = <U_ANTMORPH_MACRO_WAIT>;
            tap-ms = <U_ANTMORPH_MACRO_TAP>;
            // (j)g      
            bindings = <&macro_tap &kp G &kp SPACE &kp SPACE &kp SPACE &kp SPACE &kp SPACE &kp SPACE>;
        };
        amx64_jge: amx64_jge {
            compatible = "zmk,behavior-macro";
            #binding-cells = <0>;
            wait-ms = <U_ANTMORPH_MACRO_WAIT>;
            tap-ms = <U_ANTMORPH_MACRO_TAP>;
            // (j)ge     
            bindings = <&macro_release &kp RCTRL>, <&macro_tap &kp G &kp E &kp SPACE &kp SPACE &kp SPACE &kp SPACE &kp SPACE>;
        };
        amx64_jng: amx64_jng {
            compatible = "zmk,behavior-macro";
            #binding-cells = <0>;
            wait-ms = <U_ANTMORPH_MACRO_WAIT>;
            tap-ms = <U_ANTMORPH_MACRO_TAP>;
            // (j)ng     
            bindings = <&macro_release &kp RALT>, <&macro_tap &kp RALT>, <&macro_tap &kp N &kp G &kp SPACE &kp SPACE &kp SPACE &kp SPACE &kp SPACE>;
        };
        amx64_jnge: amx64_jnge {
            compatible = "zmk,behavior-macro";
            #binding-cells = <0>;
            wait-ms = <U_ANTMORPH_MACRO_WAIT>;
            tap-ms = <U_ANTMORPH_MACRO_TAP>;
            // (j)nge    
            bindings = <&macro_release &kp RGUI>, <&macro_tap &kp RGUI>, <&macro_tap &kp N &kp G &kp E &kp SPACE &kp SPACE &kp SPACE &kp SPACE>;
        };
        amx64_je: amx64_je {
            compatible = "zmk,behavior-macro";
            #binding-cells = <0>;
            wait-ms = <U_ANTMORPH_MACRO_WAIT>;
            tap-ms = <U_ANTMORPH_MACRO_TAP>;
            // (j)e      
            bindings = <&macro_tap &kp E &kp SPACE &kp SPACE &kp SPACE &kp SPACE &kp SPACE &kp SPACE>;
        };
        amx64_jz: amx64_jz {
            compatible = "zmk,behavior-macro";
            #binding-cells = <0>;
            wait-ms = <U_ANTMORPH_MACRO_WAIT>;
            tap-ms = <U_ANTMORPH_MACRO_TAP>;
            // (j)z      
            bindings = <&macro_release &kp RCTRL>, <&macro_tap &kp Z &kp SPACE &kp SPACE &kp SPACE &kp SPACE &kp SPACE &kp SPACE>;
        };
        amx64_jne: amx64_jne {
            compatible = "zmk,behavior-macro";
            #binding-cells = <0>;
            wait-ms = <U_ANTMORPH_MACRO_WAIT>;
            tap-ms = <U_ANTMORPH_MACRO_TAP>;
            // (j)ne     
            bindings = <&macro_release &kp RALT>, <&macro_tap &kp RALT>, <&macro_tap &kp N &kp E &kp SPACE &kp SPACE &kp SPACE &kp SPACE &kp SPACE>;
        };
        amx64_jnz: amx64_jnz {
            compatible = "zmk,behavior-macro";
            #binding-cells = <0>;
            wait-ms = <U_ANTMORPH_MACRO_WAIT>;
            tap-ms = <U_ANTMORPH_MACRO_TAP>;
            // (j)nz     
            bindings = <&macro_release &kp RGUI>, <&macro_tap &kp RGUI>, <&macro_tap &kp N &kp Z &kp SPACE &kp SPACE &kp SPACE &kp SPACE &kp SPACE>;
        };
        amx64_jl: amx64_jl {
            compatible = "zmk,behavior-macro";
            #binding-cells = <0>;
            wait-ms = <U_ANTMORPH_MACRO_WAIT>;
            tap-ms = <U_ANTMORPH_MACRO_TAP>;
            // (j)l      
            bindings = <&macro_tap &kp L &kp SPACE &kp SPACE &kp SPACE &kp SPACE &kp SPACE &kp SPACE>;
        };
        amx64_jle: amx64_jle {
            compatible = "zmk,behavior-macro";
            #binding-cells = <0>;
            wait-ms = <U_ANTMORPH_MACRO_WAIT>;
            tap-ms = <U_ANTMORPH_MACRO_TAP>;
            // (j)le     
            bindings = <&macro_release &kp RCTRL>, <&macro_tap &kp L &kp E &kp SPACE &kp SPACE &kp SPACE &kp SPACE &kp SPACE>;
        };
        amx64_jnl: amx64_jnl {
            compatible = "zmk,behavior-macro";
            #binding-cells = <0>;
            wait-ms = <U_ANTMORPH_MACRO_WAIT>;
            tap-ms = <U_ANTMORPH_MACRO_TAP>;
            // (j)nl     
            bindings = <&macro_release &kp RALT>, <&macro_tap &kp RALT>, <&macro_tap &kp N &kp L &kp SPACE &kp SPACE &kp SPACE &kp SPACE &kp SPACE>;
        };
        amx64_jnle: amx64_jnle {
            compatible = "zmk,behavior-macro";
            #binding-cells = <0>;
            wait-ms = <U_ANTMORPH_MACRO_WAIT>;
            tap-ms = <U_ANTMORPH_MACRO_TAP>;
            // (j)nle    
            bindings = <&macro_release &kp RGUI>, <&macro_tap &kp RGUI>, <&macro_tap &kp N &kp L &kp E &kp SPACE &kp SPACE &kp SPACE &kp SPACE>;
        };
        // 'L'
        amx64_lea: amx64_lea {
            compatible = "zmk,behavior-macro";
            #binding-cells = <0>;
            wait-ms = <U_ANTMORPH_MACRO_WAIT>;
            tap-ms = <U_ANTMORPH_MACRO_TAP>;
            // (l)ea     
            bindings = <&macro_tap &kp E &kp A &kp SPACE &kp SPACE &kp SPACE &kp SPACE &kp SPACE>;
        };
        amx64_loop: amx64_loop {
            compatible = "zmk,behavior-macro";
            #binding-cells = <0>;
            wait-ms = <U_ANTMORPH_MACRO_WAIT>;
            tap-ms = <U_ANTMORPH_MACRO_TAP>;
            // (l)oop    
            bindings = <&macro_tap &kp O &kp O &kp P &kp SPACE &kp SPACE &kp SPACE &kp SPACE>;
        };
        amx64_loop_loop: amx64_loop_loop {
            compatible = "zmk,behavior-macro";
            #binding-cells = <0>;
            wait-ms = <U_ANTMORPH_MACRO_WAIT>;
            tap-ms = <U_ANTMORPH_MACRO_TAP>;
            // (l)oop    .loop
            bindings = <&macro_release &kp RCTRL>, <&macro_tap &kp O &kp O &kp P &kp SPACE &kp SPACE &kp SPACE &kp SPACE &kp DOT &kp L &kp O &kp O &kp P>;
        };
        amx64_leave: amx64_leave {
            compatible = "zmk,behavior-macro";
            #binding-cells = <0>;
            wait-ms = <U_ANTMORPH_MACRO_WAIT>;
            tap-ms = <U_ANTMORPH_MACRO_TAP>;
            // (l)eave
            bindings = <&macro_tap &kp E &kp A &kp V &kp E>;
        };
        amx64_mov_rsp_rbppop_: amx64_mov_rsp_rbppop_ {
            compatible = "zmk,behavior-macro";
            #binding-cells = <0>;
            wait-ms = <U_ANTMORPH_MACRO_WAIT>;
            tap-ms = <U_ANTMORPH_MACRO_TAP>;
            // [l]mov     rsp, rbp⏎pop     rbp
            bindings = <&macro_release &kp RCTRL>, <&macro_tap &kp BSPC &kp M &kp O &kp V &kp SPACE &kp SPACE &kp SPACE &kp SPACE &kp SPACE &kp R &kp S &kp P &kp COMMA &kp SPACE &kp R &kp B &kp P &kp RET &kp P &kp O &kp P &kp SPACE &kp SPACE &kp SPACE &kp SPACE &kp SPACE &kp R &kp B &kp P>;
        };
        // 'M'
        amx64_mul: amx64_mul {
            compatible = "zmk,behavior-macro";
            #binding-cells = <0>;
            wait-ms = <U_ANTMORPH_MACRO_WAIT>;
            tap-ms = <U_ANTMORPH_MACRO_TAP>;
            // (m)ul     
            bindings = <&macro_tap &kp U &kp L &kp SPACE &kp SPACE &kp SPACE &kp SPACE &kp SPACE>;
        };
        amx64_mulsd: amx64_mulsd {
            compatible = "zmk,behavior-macro";
            #binding-cells = <0>;
            wait-ms = <U_ANTMORPH_MACRO_WAIT>;
            tap-ms = <U_ANTMORPH_MACRO_TAP>;
            // (m)ulsd   
            bindings = <&macro_release &kp LCTRL>, <&macro_tap &kp U &kp L &kp S &kp D &kp SPACE &kp SPACE &kp SPACE>;
        };
        amx64_mulss: amx64_mulss {
            compatible = "zmk,behavior-macro";
            #binding-cells = <0>;
            wait-ms = <U_ANTMORPH_MACRO_WAIT>;
            tap-ms = <U_ANTMORPH_MACRO_TAP>;
            // (m)ulss   
            bindings = <&macro_release &kp LALT>, <&macro_tap &kp LALT>, <&macro_tap &kp U &kp L &kp S &kp S &kp SPACE &kp SPACE &kp SPACE>;
        };
        amx64_movdbu: amx64_movdbu {
            compatible = "zmk,behavior-macro";
            #binding-cells = <0>;
            wait-ms = <U_ANTMORPH_MACRO_WAIT>;
            tap-ms = <U_ANTMORPH_MACRO_TAP>;
            // (m)ovdbu  
            bindings = <&macro_tap &kp O &kp V &kp D &kp B &kp U &kp SPACE &kp SPACE>;
        };
        amx64_movdwu: amx64_movdwu {
            compatible = "zmk,behavior-macro";
            #binding-cells = <0>;
            wait-ms = <U_ANTMORPH_MACRO_WAIT>;
            tap-ms = <U_ANTMORPH_MACRO_TAP>;
            // (m)ovdwu  
            bindings = <&macro_release &kp LCTRL>, <&macro_tap &kp O &kp V &kp D &kp W &kp U &kp SPACE &kp SPACE>;
        };
        amx64_movddu: amx64_movddu {
            compatible = "zmk,behavior-macro";
            #binding-cells = <0>;
            wait-ms = <U_ANTMORPH_MACRO_WAIT>;
            tap-ms = <U_ANTMORPH_MACRO_TAP>;
            // (m)ovddu  
            bindings = <&macro_release &kp LALT>, <&macro_tap &kp LALT>, <&macro_tap &kp O &kp V &kp D &kp D &kp U &kp SPACE &kp SPACE>;
        };
        amx64_movdqu: amx64_movdqu {
            compatible = "zmk,behavior-macro";
            #binding-cells = <0>;
            wait-ms = <U_ANTMORPH_MACRO_WAIT>;
            tap-ms = <U_ANTMORPH_MACRO_TAP>;
            // (m)ovdqu  
            bindings = <&macro_release &kp LGUI>, <&macro_tap &kp LGUI>, <&macro_tap &kp O &kp V &kp D &kp Q &kp U &kp SPACE &kp SPACE>;
        };
        amx64_movapd: amx64_movapd {
            compatible = "zmk,behavior-macro";
            #binding-cells = <0>;
            wait-ms = <U_ANTMORPH_MACRO_WAIT>;
            tap-ms = <U_ANTMORPH_MACRO_TAP>;
            // (m)ovapd  
            bindings = <&macro_tap &kp O &kp V &kp A &kp P &kp D &kp SPACE &kp SPACE>;
        };
        amx64_movaps: amx64_movaps {
            compatible = "zmk,behavior-macro";
            #binding-cells = <0>;
            wait-ms = <U_ANTMORPH_MACRO_WAIT>;
            tap-ms = <U_ANTMORPH_MACRO_TAP>;
            // (m)ovaps  
            bindings = <&macro_release &kp RCTRL>, <&macro_tap &kp O &kp V &kp A &kp P &kp S &kp SPACE &kp SPACE>;
        };
        amx64_movupd: amx64_movupd {
            compatible = "zmk,behavior-macro";
            #binding-cells = <0>;
            wait-ms = <U_ANTMORPH_MACRO_WAIT>;
            tap-ms = <U_ANTMORPH_MACRO_TAP>;
            // (m)ovupd  
            bindings = <&macro_release &kp RALT>, <&macro_tap &kp RALT>, <&macro_tap &kp O &kp V &kp U &kp P &kp D &kp SPACE &kp SPACE>;
        };
        amx64_movups: amx64_movups {
            compatible = "zmk,behavior-macro";
            #binding-cells = <0>;
            wait-ms = <U_ANTMORPH_MACRO_WAIT>;
            tap-ms = <U_ANTMORPH_MACRO_TAP>;
            // (m)ovups  
            bindings = <&macro_release &kp RGUI>, <&macro_tap &kp RGUI>, <&macro_tap &kp O &kp V &kp U &kp P &kp S &kp SPACE &kp SPACE>;
        };
        amx64_mov: amx64_mov {
            compatible = "zmk,behavior-macro";
            #binding-cells = <0>;
            wait-ms = <U_ANTMORPH_MACRO_WAIT>;
            tap-ms = <U_ANTMORPH_MACRO_TAP>;
            // (m)ov     
            bindings = <&macro_tap &kp O &kp V &kp SPACE &kp SPACE &kp SPACE &kp SPACE &kp SPACE>;
        };
        amx64_movsd: amx64_movsd {
            compatible = "zmk,behavior-macro";
            #binding-cells = <0>;
            wait-ms = <U_ANTMORPH_MACRO_WAIT>;
            tap-ms = <U_ANTMORPH_MACRO_TAP>;
            // (m)ovsd   
            bindings = <&macro_release &kp RCTRL>, <&macro_tap &kp O &kp V &kp S &kp D &kp SPACE &kp SPACE &kp SPACE>;
        };
        amx64_movss: amx64_movss {
            compatible = "zmk,behavior-macro";
            #binding-cells = <0>;
            wait-ms = <U_ANTMORPH_MACRO_WAIT>;
            tap-ms = <U_ANTMORPH_MACRO_TAP>;
            // (m)ovss   
            bindings = <&macro_release &kp RALT>, <&macro_tap &kp RALT>, <&macro_tap &kp O &kp V &kp S &kp S &kp SPACE &kp SPACE &kp SPACE>;
        };
        amx64_movdba: amx64_movdba {
            compatible = "zmk,behavior-macro";
            #binding-cells = <0>;
            wait-ms = <U_ANTMORPH_MACRO_WAIT>;
            tap-ms = <U_ANTMORPH_MACRO_TAP>;
            // (m)ovdba  
            bindings = <&macro_tap &kp O &kp V &kp D &kp B &kp A &kp SPACE &kp SPACE>;
        };
        amx64_movdwa: amx64_movdwa {
            compatible = "zmk,behavior-macro";
            #binding-cells = <0>;
            wait-ms = <U_ANTMORPH_MACRO_WAIT>;
            tap-ms = <U_ANTMORPH_MACRO_TAP>;
            // (m)ovdwa  
            bindings = <&macro_release &kp RCTRL>, <&macro_tap &kp O &kp V &kp D &kp W &kp A &kp SPACE &kp SPACE>;
        };
        amx64_movdda: amx64_movdda {
            compatible = "zmk,behavior-macro";
            #binding-cells = <0>;
            wait-ms = <U_ANTMORPH_MACRO_WAIT>;
            tap-ms = <U_ANTMORPH_MACRO_TAP>;
            // (m)ovdda  
            bindings = <&macro_release &kp RALT>, <&macro_tap &kp RALT>, <&macro_tap &kp O &kp V &kp D &kp D &kp A &kp SPACE &kp SPACE>;
        };
        amx64_movdqa: amx64_movdqa {
            compatible = "zmk,behavior-macro";
            #binding-cells = <0>;
            wait-ms = <U_ANTMORPH_MACRO_WAIT>;
            tap-ms = <U_ANTMORPH_MACRO_TAP>;
            // (m)ovdqa  
            bindings = <&macro_release &kp RGUI>, <&macro_tap &kp RGUI>, <&macro_tap &kp O &kp V &kp D &kp Q &kp A &kp SPACE &kp SPACE>;
        };
        // 'N'
        amx64_not: amx64_not {
            compatible = "zmk,behavior-macro";
            #binding-cells = <0>;
            wait-ms = <U_ANTMORPH_MACRO_WAIT>;
            tap-ms = <U_ANTMORPH_MACRO_TAP>;
            // (n)ot     
            bindings = <&macro_tap &kp O &kp T &kp SPACE &kp SPACE &kp SPACE &kp SPACE &kp SPACE>;
        };
        amx64_neg: amx64_neg {
            compatible = "zmk,behavior-macro";
            #binding-cells = <0>;
            wait-ms = <U_ANTMORPH_MACRO_WAIT>;
            tap-ms = <U_ANTMORPH_MACRO_TAP>;
            // (n)eg      
            bindings = <&macro_tap &kp E &kp G &kp SPACE &kp SPACE &kp SPACE &kp SPACE &kp SPACE &kp SPACE>;
        };
        // 'O'
        amx64_or: amx64_or {
            compatible = "zmk,behavior-macro";
            #binding-cells = <0>;
            wait-ms = <U_ANTMORPH_MACRO_WAIT>;
            tap-ms = <U_ANTMORPH_MACRO_TAP>;
            // (o)r      
            bindings = <&macro_tap &kp R &kp SPACE &kp SPACE &kp SPACE &kp SPACE &kp SPACE &kp SPACE>;
        };
        // 'P'
        amx64_pop: amx64_pop {
            compatible = "zmk,behavior-macro";
            #binding-cells = <0>;
            wait-ms = <U_ANTMORPH_MACRO_WAIT>;
            tap-ms = <U_ANTMORPH_MACRO_TAP>;
            // (p)op     
            bindings = <&macro_tap &kp O &kp P &kp SPACE &kp SPACE &kp SPACE &kp SPACE &kp SPACE>;
        };
        amx64_push: amx64_push {
            compatible = "zmk,behavior-macro";
            #binding-cells = <0>;
            wait-ms = <U_ANTMORPH_MACRO_WAIT>;
            tap-ms = <U_ANTMORPH_MACRO_TAP>;
            // (p)ush    
            bindings = <&macro_tap &kp U &kp S &kp H &kp SPACE &kp SPACE &kp SPACE &kp SPACE>;
        };
        amx64_pextrb: amx64_pextrb {
            compatible = "zmk,behavior-macro";
            #binding-cells = <0>;
            wait-ms = <U_ANTMORPH_MACRO_WAIT>;
            tap-ms = <U_ANTMORPH_MACRO_TAP>;
            // (p)extrb  
            bindings = <&macro_tap &kp E &kp X &kp T &kp R &kp B &kp SPACE &kp SPACE>;
        };
        amx64_pextrw: amx64_pextrw {
            compatible = "zmk,behavior-macro";
            #binding-cells = <0>;
            wait-ms = <U_ANTMORPH_MACRO_WAIT>;
            tap-ms = <U_ANTMORPH_MACRO_TAP>;
            // (p)extrw  
            bindings = <&macro_release &kp LCTRL>, <&macro_tap &kp E &kp X &kp T &kp R &kp W &kp SPACE &kp SPACE>;
        };
        amx64_pextrd: amx64_pextrd {
            compatible = "zmk,behavior-macro";
            #binding-cells = <0>;
            wait-ms = <U_ANTMORPH_MACRO_WAIT>;
            tap-ms = <U_ANTMORPH_MACRO_TAP>;
            // (p)extrd  
            bindings = <&macro_release &kp LALT>, <&macro_tap &kp LALT>, <&macro_tap &kp E &kp X &kp T &kp R &kp D &kp SPACE &kp SPACE>;
        };
        amx64_pextrq: amx64_pextrq {
            compatible = "zmk,behavior-macro";
            #binding-cells = <0>;
            wait-ms = <U_ANTMORPH_MACRO_WAIT>;
            tap-ms = <U_ANTMORPH_MACRO_TAP>;
            // (p)extrq  
            bindings = <&macro_release &kp LGUI>, <&macro_tap &kp LGUI>, <&macro_tap &kp E &kp X &kp T &kp R &kp Q &kp SPACE &kp SPACE>;
        };
        amx64_rsp_rsp: amx64_rsp_rsp {
            compatible = "zmk,behavior-macro";
            #binding-cells = <0>;
            wait-ms = <U_ANTMORPH_MACRO_WAIT>;
            tap-ms = <U_ANTMORPH_MACRO_TAP>;
            // [p]rsp, rsp
            bindings = <&macro_tap &kp BSPC &kp R &kp S &kp P &kp COMMA &kp SPACE &kp R &kp S &kp P>;
        };
        amx64_rbp_rbp: amx64_rbp_rbp {
            compatible = "zmk,behavior-macro";
            #binding-cells = <0>;
            wait-ms = <U_ANTMORPH_MACRO_WAIT>;
            tap-ms = <U_ANTMORPH_MACRO_TAP>;
            // [p]rbp, rbp
            bindings = <&macro_tap &kp BSPC &kp R &kp B &kp P &kp COMMA &kp SPACE &kp R &kp B &kp P>;
        };
        amx64_pinsrb: amx64_pinsrb {
            compatible = "zmk,behavior-macro";
            #binding-cells = <0>;
            wait-ms = <U_ANTMORPH_MACRO_WAIT>;
            tap-ms = <U_ANTMORPH_MACRO_TAP>;
            // (p)insrb  
            bindings = <&macro_tap &kp I &kp N &kp S &kp R &kp B &kp SPACE &kp SPACE>;
        };
        amx64_pinsrw: amx64_pinsrw {
            compatible = "zmk,behavior-macro";
            #binding-cells = <0>;
            wait-ms = <U_ANTMORPH_MACRO_WAIT>;
            tap-ms = <U_ANTMORPH_MACRO_TAP>;
            // (p)insrw  
            bindings = <&macro_release &kp RCTRL>, <&macro_tap &kp I &kp N &kp S &kp R &kp W &kp SPACE &kp SPACE>;
        };
        amx64_pinsrd: amx64_pinsrd {
            compatible = "zmk,behavior-macro";
            #binding-cells = <0>;
            wait-ms = <U_ANTMORPH_MACRO_WAIT>;
            tap-ms = <U_ANTMORPH_MACRO_TAP>;
            // (p)insrd  
            bindings = <&macro_release &kp RALT>, <&macro_tap &kp RALT>, <&macro_tap &kp I &kp N &kp S &kp R &kp D &kp SPACE &kp SPACE>;
        };
        amx64_pinsrq: amx64_pinsrq {
            compatible = "zmk,behavior-macro";
            #binding-cells = <0>;
            wait-ms = <U_ANTMORPH_MACRO_WAIT>;
            tap-ms = <U_ANTMORPH_MACRO_TAP>;
            // (p)insrq  
            bindings = <&macro_release &kp RGUI>, <&macro_tap &kp RGUI>, <&macro_tap &kp I &kp N &kp S &kp R &kp Q &kp SPACE &kp SPACE>;
        };
        // 'Q'
        amx64_qword: amx64_qword {
            compatible = "zmk,behavior-macro";
            #binding-cells = <0>;
            wait-ms = <U_ANTMORPH_MACRO_WAIT>;
            tap-ms = <U_ANTMORPH_MACRO_TAP>;
            // (q)word
            bindings = <&macro_tap &kp W &kp O &kp R &kp D>;
        };
        // 'R'
        amx64_repe_cmps: amx64_repe_cmps {
            compatible = "zmk,behavior-macro";
            #binding-cells = <0>;
            wait-ms = <U_ANTMORPH_MACRO_WAIT>;
            tap-ms = <U_ANTMORPH_MACRO_TAP>;
            // (r)epe cmps
            bindings = <&macro_tap &kp E &kp P &kp E &kp SPACE &kp C &kp M &kp P &kp S>;
        };
        amx64_repz_cmps: amx64_repz_cmps {
            compatible = "zmk,behavior-macro";
            #binding-cells = <0>;
            wait-ms = <U_ANTMORPH_MACRO_WAIT>;
            tap-ms = <U_ANTMORPH_MACRO_TAP>;
            // (r)epz cmps
            bindings = <&macro_release &kp LCTRL>, <&macro_tap &kp E &kp P &kp Z &kp SPACE &kp C &kp M &kp P &kp S>;
        };
        amx64_repne_cmps: amx64_repne_cmps {
            compatible = "zmk,behavior-macro";
            #binding-cells = <0>;
            wait-ms = <U_ANTMORPH_MACRO_WAIT>;
            tap-ms = <U_ANTMORPH_MACRO_TAP>;
            // (r)epne cmps
            bindings = <&macro_release &kp LALT>, <&macro_tap &kp LALT>, <&macro_tap &kp E &kp P &kp N &kp E &kp SPACE &kp C &kp M &kp P &kp S>;
        };
        amx64_repnz_cmps: amx64_repnz_cmps {
            compatible = "zmk,behavior-macro";
            #binding-cells = <0>;
            wait-ms = <U_ANTMORPH_MACRO_WAIT>;
            tap-ms = <U_ANTMORPH_MACRO_TAP>;
            // (r)epnz cmps
            bindings = <&macro_release &kp LGUI>, <&macro_tap &kp LGUI>, <&macro_tap &kp E &kp P &kp N &kp Z &kp SPACE &kp C &kp M &kp P &kp S>;
        };
        amx64_rep_stos: amx64_rep_stos {
            compatible = "zmk,behavior-macro";
            #binding-cells = <0>;
            wait-ms = <U_ANTMORPH_MACRO_WAIT>;
            tap-ms = <U_ANTMORPH_MACRO_TAP>;
            // (r)ep stos
            bindings = <&macro_tap &kp E &kp P &kp SPACE &kp S &kp T &kp O &kp S>;
        };
        amx64_rep_movs: amx64_rep_movs {
            compatible = "zmk,behavior-macro";
            #binding-cells = <0>;
            wait-ms = <U_ANTMORPH_MACRO_WAIT>;
            tap-ms = <U_ANTMORPH_MACRO_TAP>;
            // (r)ep movs
            bindings = <&macro_release &kp LCTRL>, <&macro_tap &kp E &kp P &kp SPACE &kp M &kp O &kp V &kp S>;
        };
        amx64_resb: amx64_resb {
            compatible = "zmk,behavior-macro";
            #binding-cells = <0>;
            wait-ms = <U_ANTMORPH_MACRO_WAIT>;
            tap-ms = <U_ANTMORPH_MACRO_TAP>;
            // (r)esb 
            bindings = <&macro_tap &kp E &kp S &kp B &kp SPACE>;
        };
        amx64_resw: amx64_resw {
            compatible = "zmk,behavior-macro";
            #binding-cells = <0>;
            wait-ms = <U_ANTMORPH_MACRO_WAIT>;
            tap-ms = <U_ANTMORPH_MACRO_TAP>;
            // (r)esw 
            bindings = <&macro_release &kp LCTRL>, <&macro_tap &kp E &kp S &kp W &kp SPACE>;
        };
        amx64_resd: amx64_resd {
            compatible = "zmk,behavior-macro";
            #binding-cells = <0>;
            wait-ms = <U_ANTMORPH_MACRO_WAIT>;
            tap-ms = <U_ANTMORPH_MACRO_TAP>;
            // (r)esd 
            bindings = <&macro_release &kp LALT>, <&macro_tap &kp LALT>, <&macro_tap &kp E &kp S &kp D &kp SPACE>;
        };
        amx64_resq: amx64_resq {
            compatible = "zmk,behavior-macro";
            #binding-cells = <0>;
            wait-ms = <U_ANTMORPH_MACRO_WAIT>;
            tap-ms = <U_ANTMORPH_MACRO_TAP>;
            // (r)esq 
            bindings = <&macro_release &kp LGUI>, <&macro_tap &kp LGUI>, <&macro_tap &kp E &kp S &kp Q &kp SPACE>;
        };
        amx64_repe_scas: amx64_repe_scas {
            compatible = "zmk,behavior-macro";
            #binding-cells = <0>;
            wait-ms = <U_ANTMORPH_MACRO_WAIT>;
            tap-ms = <U_ANTMORPH_MACRO_TAP>;
            // (r)epe scas
            bindings = <&macro_tap &kp E &kp P &kp E &kp SPACE &kp S &kp C &kp A &kp S>;
        };
        amx64_repz_scas: amx64_repz_scas {
            compatible = "zmk,behavior-macro";
            #binding-cells = <0>;
            wait-ms = <U_ANTMORPH_MACRO_WAIT>;
            tap-ms = <U_ANTMORPH_MACRO_TAP>;
            // (r)epz scas
            bindings = <&macro_release &kp RCTRL>, <&macro_tap &kp E &kp P &kp Z &kp SPACE &kp S &kp C &kp A &kp S>;
        };
        amx64_repne_scas: amx64_repne_scas {
            compatible = "zmk,behavior-macro";
            #binding-cells = <0>;
            wait-ms = <U_ANTMORPH_MACRO_WAIT>;
            tap-ms = <U_ANTMORPH_MACRO_TAP>;
            // (r)epne scas
            bindings = <&macro_release &kp RALT>, <&macro_tap &kp RALT>, <&macro_tap &kp E &kp P &kp N &kp E &kp SPACE &kp S &kp C &kp A &kp S>;
        };
        amx64_repnz_scas: amx64_repnz_scas {
            compatible = "zmk,behavior-macro";
            #binding-cells = <0>;
            wait-ms = <U_ANTMORPH_MACRO_WAIT>;
            tap-ms = <U_ANTMORPH_MACRO_TAP>;
            // (r)epnz scas
            bindings = <&macro_release &kp RGUI>, <&macro_tap &kp RGUI>, <&macro_tap &kp E &kp P &kp N &kp Z &kp SPACE &kp S &kp C &kp A &kp S>;
        };
        amx64_rol: amx64_rol {
            compatible = "zmk,behavior-macro";
            #binding-cells = <0>;
            wait-ms = <U_ANTMORPH_MACRO_WAIT>;
            tap-ms = <U_ANTMORPH_MACRO_TAP>;
            // (r)ol     
            bindings = <&macro_tap &kp O &kp L &kp SPACE &kp SPACE &kp SPACE &kp SPACE &kp SPACE>;
        };
        amx64_ror: amx64_ror {
            compatible = "zmk,behavior-macro";
            #binding-cells = <0>;
            wait-ms = <U_ANTMORPH_MACRO_WAIT>;
            tap-ms = <U_ANTMORPH_MACRO_TAP>;
            // (r)or     
            bindings = <&macro_release &kp RCTRL>, <&macro_tap &kp O &kp R &kp SPACE &kp SPACE &kp SPACE &kp SPACE &kp SPACE>;
        };
        // 'S'
        amx64_section: amx64_section {
            compatible = "zmk,behavior-macro";
            #binding-cells = <0>;
            wait-ms = <U_ANTMORPH_MACRO_WAIT>;
            tap-ms = <U_ANTMORPH_MACRO_TAP>;
            // (s)ection 
            bindings = <&macro_tap &kp E &kp C &kp T &kp I &kp O &kp N &kp SPACE>;
        };
        amx64_section_data: amx64_section_data {
            compatible = "zmk,behavior-macro";
            #binding-cells = <0>;
            wait-ms = <U_ANTMORPH_MACRO_WAIT>;
            tap-ms = <U_ANTMORPH_MACRO_TAP>;
            // (s)ection .data
            bindings = <&macro_release &kp LCTRL>, <&macro_tap &kp E &kp C &kp T &kp I &kp O &kp N &kp SPACE &kp DOT &kp D &kp A &kp T &kp A>;
        };
        amx64_section_text: amx64_section_text {
            compatible = "zmk,behavior-macro";
            #binding-cells = <0>;
            wait-ms = <U_ANTMORPH_MACRO_WAIT>;
            tap-ms = <U_ANTMORPH_MACRO_TAP>;
            // (s)ection .text
            bindings = <&macro_release &kp LALT>, <&macro_tap &kp LALT>, <&macro_tap &kp E &kp C &kp T &kp I &kp O &kp N &kp SPACE &kp DOT &kp T &kp E &kp X &kp T>;
        };
        amx64_section_bss: amx64_section_bss {
            compatible = "zmk,behavior-macro";
            #binding-cells = <0>;
            wait-ms = <U_ANTMORPH_MACRO_WAIT>;
            tap-ms = <U_ANTMORPH_MACRO_TAP>;
            // (s)ection .bss
            bindings = <&macro_release &kp LGUI>, <&macro_tap &kp LGUI>, <&macro_tap &kp E &kp C &kp T &kp I &kp O &kp N &kp SPACE &kp DOT &kp B &kp S &kp S>;
        };
        amx64_sub: amx64_sub {
            compatible = "zmk,behavior-macro";
            #binding-cells = <0>;
            wait-ms = <U_ANTMORPH_MACRO_WAIT>;
            tap-ms = <U_ANTMORPH_MACRO_TAP>;
            // (s)ub     
            bindings = <&macro_tap &kp U &kp B &kp SPACE &kp SPACE &kp SPACE &kp SPACE &kp SPACE>;
        };
        amx64_subsd: amx64_subsd {
            compatible = "zmk,behavior-macro";
            #binding-cells = <0>;
            wait-ms = <U_ANTMORPH_MACRO_WAIT>;
            tap-ms = <U_ANTMORPH_MACRO_TAP>;
            // (s)ubsd   
            bindings = <&macro_release &kp LCTRL>, <&macro_tap &kp U &kp B &kp S &kp D &kp SPACE &kp SPACE &kp SPACE>;
        };
        amx64_subss: amx64_subss {
            compatible = "zmk,behavior-macro";
            #binding-cells = <0>;
            wait-ms = <U_ANTMORPH_MACRO_WAIT>;
            tap-ms = <U_ANTMORPH_MACRO_TAP>;
            // (s)ubss   
            bindings = <&macro_release &kp LALT>, <&macro_tap &kp LALT>, <&macro_tap &kp U &kp B &kp S &kp S &kp SPACE &kp SPACE &kp SPACE>;
        };
        amx64_syscall: amx64_syscall {
            compatible = "zmk,behavior-macro";
            #binding-cells = <0>;
            wait-ms = <U_ANTMORPH_MACRO_WAIT>;
            tap-ms = <U_ANTMORPH_MACRO_TAP>;
            // (s)yscall
            bindings = <&macro_tap &kp Y &kp S &kp C &kp A &kp L &kp L>;
        };
        amx64_sar: amx64_sar {
            compatible = "zmk,behavior-macro";
            #binding-cells = <0>;
            wait-ms = <U_ANTMORPH_MACRO_WAIT>;
            tap-ms = <U_ANTMORPH_MACRO_TAP>;
            // (s)ar     
            bindings = <&macro_tap &kp A &kp R &kp SPACE &kp SPACE &kp SPACE &kp SPACE &kp SPACE>;
        };
        amx64_shr: amx64_shr {
            compatible = "zmk,behavior-macro";
            #binding-cells = <0>;
            wait-ms = <U_ANTMORPH_MACRO_WAIT>;
            tap-ms = <U_ANTMORPH_MACRO_TAP>;
            // (s)hr     
            bindings = <&macro_release &kp RCTRL>, <&macro_tap &kp H &kp R &kp SPACE &kp SPACE &kp SPACE &kp SPACE &kp SPACE>;
        };
        amx64_sal: amx64_sal {
            compatible = "zmk,behavior-macro";
            #binding-cells = <0>;
            wait-ms = <U_ANTMORPH_MACRO_WAIT>;
            tap-ms = <U_ANTMORPH_MACRO_TAP>;
            // (s)al     
            bindings = <&macro_tap &kp A &kp L &kp SPACE &kp SPACE &kp SPACE &kp SPACE &kp SPACE>;
        };
        amx64_shl: amx64_shl {
            compatible = "zmk,behavior-macro";
            #binding-cells = <0>;
            wait-ms = <U_ANTMORPH_MACRO_WAIT>;
            tap-ms = <U_ANTMORPH_MACRO_TAP>;
            // (s)hl     
            bindings = <&macro_release &kp RCTRL>, <&macro_tap &kp H &kp L &kp SPACE &kp SPACE &kp SPACE &kp SPACE &kp SPACE>;
        };
        amx64_sqrtsd: amx64_sqrtsd {
            compatible = "zmk,behavior-macro";
            #binding-cells = <0>;
            wait-ms = <U_ANTMORPH_MACRO_WAIT>;
            tap-ms = <U_ANTMORPH_MACRO_TAP>;
            // (s)qrtsd  
            bindings = <&macro_tap &kp Q &kp R &kp T &kp S &kp D &kp SPACE &kp SPACE>;
        };
        // 'T'
        amx64_0123456789: amx64_0123456789 {
            compatible = "zmk,behavior-macro";
            #binding-cells = <0>;
            wait-ms = <U_ANTMORPH_MACRO_WAIT>;
            tap-ms = <U_ANTMORPH_MACRO_TAP>;
            // [t]0123456789
            bindings = <&macro_tap &kp BSPC &kp N0 &kp N1 &kp N2 &kp N3 &kp N4 &kp N5 &kp N6 &kp N7 &kp N8 &kp N9>;
        };
        amx64_1234567890: amx64_1234567890 {
            compatible = "zmk,behavior-macro";
            #binding-cells = <0>;
            wait-ms = <U_ANTMORPH_MACRO_WAIT>;
            tap-ms = <U_ANTMORPH_MACRO_TAP>;
            // [t]1234567890
            bindings = <&macro_release &kp LCTRL>, <&macro_tap &kp BSPC &kp N1 &kp N2 &kp N3 &kp N4 &kp N5 &kp N6 &kp N7 &kp N8 &kp N9 &kp N0>;
        };
        amx64_test: amx64_test {
            compatible = "zmk,behavior-macro";
            #binding-cells = <0>;
            wait-ms = <U_ANTMORPH_MACRO_WAIT>;
            tap-ms = <U_ANTMORPH_MACRO_TAP>;
            // (t)est    
            bindings = <&macro_tap &kp E &kp S &kp T &kp SPACE &kp SPACE &kp SPACE &kp SPACE>;
        };
        amx64_0123456789abcde: amx64_0123456789abcde {
            compatible = "zmk,behavior-macro";
            #binding-cells = <0>;
            wait-ms = <U_ANTMORPH_MACRO_WAIT>;
            tap-ms = <U_ANTMORPH_MACRO_TAP>;
            // [t]0123456789abcdef
            bindings = <&macro_tap &kp BSPC &kp N0 &kp N1 &kp N2 &kp N3 &kp N4 &kp N5 &kp N6 &kp N7 &kp N8 &kp N9 &kp A &kp B &kp C &kp D &kp E &kp F>;
        };
        amx64_123456789abcdef: amx64_123456789abcdef {
            compatible = "zmk,behavior-macro";
            #binding-cells = <0>;
            wait-ms = <U_ANTMORPH_MACRO_WAIT>;
            tap-ms = <U_ANTMORPH_MACRO_TAP>;
            // [t]123456789abcdef0
            bindings = <&macro_release &kp LCTRL>, <&macro_tap &kp BSPC &kp N1 &kp N2 &kp N3 &kp N4 &kp N5 &kp N6 &kp N7 &kp N8 &kp N9 &kp A &kp B &kp C &kp D &kp E &kp F &kp N0>;
        };
        amx64_times: amx64_times {
            compatible = "zmk,behavior-macro";
            #binding-cells = <0>;
            wait-ms = <U_ANTMORPH_MACRO_WAIT>;
            tap-ms = <U_ANTMORPH_MACRO_TAP>;
            // (t)imes 
            bindings = <&macro_tap &kp I &kp M &kp E &kp S &kp SPACE>;
        };
        amx64_76543210: amx64_76543210 {
            compatible = "zmk,behavior-macro";
            #binding-cells = <0>;
            wait-ms = <U_ANTMORPH_MACRO_WAIT>;
            tap-ms = <U_ANTMORPH_MACRO_TAP>;
            // [t]76543210
            bindings = <&macro_tap &kp BSPC &kp N7 &kp N6 &kp N5 &kp N4 &kp N3 &kp N2 &kp N1 &kp N0>;
        };
        amx64_1__0: amx64_1__0 {
            compatible = "zmk,behavior-macro";
            #binding-cells = <0>;
            wait-ms = <U_ANTMORPH_MACRO_WAIT>;
            tap-ms = <U_ANTMORPH_MACRO_TAP>;
            // [t] '    1    '    0
            bindings = <&macro_release &kp RCTRL>, <&macro_tap &kp BSPC &kp SPACE &kp APOS &kp SPACE &kp SPACE &kp SPACE &kp SPACE &kp N1 &kp SPACE &kp SPACE &kp SPACE &kp SPACE &kp APOS &kp SPACE &kp SPACE &kp SPACE &kp SPACE &kp N0>;
        };
        amx64_3__2__1__0: amx64_3__2__1__0 {
            compatible = "zmk,behavior-macro";
            #binding-cells = <0>;
            wait-ms = <U_ANTMORPH_MACRO_WAIT>;
            tap-ms = <U_ANTMORPH_MACRO_TAP>;
            // [t]  3    '    2    '    1    '    0
            bindings = <&macro_release &kp RALT>, <&macro_tap &kp RALT>, <&macro_tap &kp BSPC &kp SPACE &kp SPACE &kp N3 &kp SPACE &kp SPACE &kp SPACE &kp SPACE &kp APOS &kp SPACE &kp SPACE &kp SPACE &kp SPACE &kp N2 &kp SPACE &kp SPACE &kp SPACE &kp SPACE &kp APOS &kp SPACE &kp SPACE &kp SPACE &kp SPACE &kp N1 &kp SPACE &kp SPACE &kp SPACE &kp SPACE &kp APOS &kp SPACE &kp SPACE &kp SPACE &kp SPACE &kp N0>;
        };
        amx64_6__5__4__3__2__: amx64_6__5__4__3__2__ {
            compatible = "zmk,behavior-macro";
            #binding-cells = <0>;
            wait-ms = <U_ANTMORPH_MACRO_WAIT>;
            tap-ms = <U_ANTMORPH_MACRO_TAP>;
            // [t]   6    '    5    '    4    '    3    '    2    '    1    '    0
            bindings = <&macro_release &kp RGUI>, <&macro_tap &kp RGUI>, <&macro_tap &kp BSPC &kp SPACE &kp SPACE &kp SPACE &kp N6 &kp SPACE &kp SPACE &kp SPACE &kp SPACE &kp APOS &kp SPACE &kp SPACE &kp SPACE &kp SPACE &kp N5 &kp SPACE &kp SPACE &kp SPACE &kp SPACE &kp APOS &kp SPACE &kp SPACE &kp SPACE &kp SPACE &kp N4 &kp SPACE &kp SPACE &kp SPACE &kp SPACE &kp APOS &kp SPACE &kp SPACE &kp SPACE &kp SPACE &kp N3 &kp SPACE &kp SPACE &kp SPACE &kp SPACE &kp APOS &kp SPACE &kp SPACE &kp SPACE &kp SPACE &kp N2 &kp SPACE &kp SPACE &kp SPACE &kp SPACE &kp APOS &kp SPACE &kp SPACE &kp SPACE &kp SPACE &kp N1 &kp SPACE &kp SPACE &kp SPACE &kp SPACE &kp APOS &kp SPACE &kp SPACE &kp SPACE &kp SPACE &kp N0>;
        };
        // 'V'
        amx64_vextractf128: amx64_vextractf128 {
            compatible = "zmk,behavior-macro";
            #binding-cells = <0>;
            wait-ms = <U_ANTMORPH_MACRO_WAIT>;
            tap-ms = <U_ANTMORPH_MACRO_TAP>;
            // (v)extractf128 
            bindings = <&macro_tap &kp E &kp X &kp T &kp R &kp A &kp C &kp T &kp F &kp N1 &kp N2 &kp N8 &kp SPACE>;
        };
        amx64_vextracti128: amx64_vextracti128 {
            compatible = "zmk,behavior-macro";
            #binding-cells = <0>;
            wait-ms = <U_ANTMORPH_MACRO_WAIT>;
            tap-ms = <U_ANTMORPH_MACRO_TAP>;
            // (v)extracti128 
            bindings = <&macro_release &kp LCTRL>, <&macro_tap &kp E &kp X &kp T &kp R &kp A &kp C &kp T &kp I &kp N1 &kp N2 &kp N8 &kp SPACE>;
        };
        amx64_vmovapd: amx64_vmovapd {
            compatible = "zmk,behavior-macro";
            #binding-cells = <0>;
            wait-ms = <U_ANTMORPH_MACRO_WAIT>;
            tap-ms = <U_ANTMORPH_MACRO_TAP>;
            // (v)movapd 
            bindings = <&macro_tap &kp M &kp O &kp V &kp A &kp P &kp D &kp SPACE>;
        };
        amx64_vmovaps: amx64_vmovaps {
            compatible = "zmk,behavior-macro";
            #binding-cells = <0>;
            wait-ms = <U_ANTMORPH_MACRO_WAIT>;
            tap-ms = <U_ANTMORPH_MACRO_TAP>;
            // (v)movaps 
            bindings = <&macro_release &kp RCTRL>, <&macro_tap &kp M &kp O &kp V &kp A &kp P &kp S &kp SPACE>;
        };
        amx64_vmovupd: amx64_vmovupd {
            compatible = "zmk,behavior-macro";
            #binding-cells = <0>;
            wait-ms = <U_ANTMORPH_MACRO_WAIT>;
            tap-ms = <U_ANTMORPH_MACRO_TAP>;
            // (v)movupd 
            bindings = <&macro_release &kp RALT>, <&macro_tap &kp RALT>, <&macro_tap &kp M &kp O &kp V &kp U &kp P &kp D &kp SPACE>;
        };
        amx64_vmovups: amx64_vmovups {
            compatible = "zmk,behavior-macro";
            #binding-cells = <0>;
            wait-ms = <U_ANTMORPH_MACRO_WAIT>;
            tap-ms = <U_ANTMORPH_MACRO_TAP>;
            // (v)movups 
            bindings = <&macro_release &kp RGUI>, <&macro_tap &kp RGUI>, <&macro_tap &kp M &kp O &kp V &kp U &kp P &kp S &kp SPACE>;
        };
        amx64_vzeroall: amx64_vzeroall {
            compatible = "zmk,behavior-macro";
            #binding-cells = <0>;
            wait-ms = <U_ANTMORPH_MACRO_WAIT>;
            tap-ms = <U_ANTMORPH_MACRO_TAP>;
            // (v)zeroall
            bindings = <&macro_tap &kp Z &kp E &kp R &kp O &kp A &kp L &kp L>;
        };
        amx64_vinsertf128: amx64_vinsertf128 {
            compatible = "zmk,behavior-macro";
            #binding-cells = <0>;
            wait-ms = <U_ANTMORPH_MACRO_WAIT>;
            tap-ms = <U_ANTMORPH_MACRO_TAP>;
            // (v)insertf128 
            bindings = <&macro_tap &kp I &kp N &kp S &kp E &kp R &kp T &kp F &kp N1 &kp N2 &kp N8 &kp SPACE>;
        };
        amx64_vinserti128: amx64_vinserti128 {
            compatible = "zmk,behavior-macro";
            #binding-cells = <0>;
            wait-ms = <U_ANTMORPH_MACRO_WAIT>;
            tap-ms = <U_ANTMORPH_MACRO_TAP>;
            // (v)inserti128 
            bindings = <&macro_release &kp RCTRL>, <&macro_tap &kp I &kp N &kp S &kp E &kp R &kp T &kp I &kp N1 &kp N2 &kp N8 &kp SPACE>;
        };
        // 'W'
        amx64_word: amx64_word {
            compatible = "zmk,behavior-macro";
            #binding-cells = <0>;
            wait-ms = <U_ANTMORPH_MACRO_WAIT>;
            tap-ms = <U_ANTMORPH_MACRO_TAP>;
            // (w)ord
            bindings = <&macro_tap &kp O &kp R &kp D>;
        };
        // 'X'
        amx64_xor: amx64_xor {
            compatible = "zmk,behavior-macro";
            #binding-cells = <0>;
            wait-ms = <U_ANTMORPH_MACRO_WAIT>;
            tap-ms = <U_ANTMORPH_MACRO_TAP>;
            // (x)or     
            bindings = <&macro_tap &kp O &kp R &kp SPACE &kp SPACE &kp SPACE &kp SPACE &kp SPACE>;
        };
        amx64_xor_rax_rax: amx64_xor_rax_rax {
            compatible = "zmk,behavior-macro";
            #binding-cells = <0>;
            wait-ms = <U_ANTMORPH_MACRO_WAIT>;
            tap-ms = <U_ANTMORPH_MACRO_TAP>;
            // (x)or     rax, rax
            bindings = <&macro_release &kp LGUI>, <&macro_tap &kp LGUI>, <&macro_tap &kp O &kp R &kp SPACE &kp SPACE &kp SPACE &kp SPACE &kp SPACE &kp R &kp A &kp X &kp COMMA &kp SPACE &kp R &kp A &kp X>;
        };
        amx64_xorpd: amx64_xorpd {
            compatible = "zmk,behavior-macro";
            #binding-cells = <0>;
            wait-ms = <U_ANTMORPH_MACRO_WAIT>;
            tap-ms = <U_ANTMORPH_MACRO_TAP>;
            // (x)orpd   
            bindings = <&macro_tap &kp O &kp R &kp P &kp D &kp SPACE &kp SPACE &kp SPACE>;
        };
        amx64_xorps: amx64_xorps {
            compatible = "zmk,behavior-macro";
            #binding-cells = <0>;
            wait-ms = <U_ANTMORPH_MACRO_WAIT>;
            tap-ms = <U_ANTMORPH_MACRO_TAP>;
            // (x)orps   
            bindings = <&macro_release &kp LCTRL>, <&macro_tap &kp O &kp R &kp P &kp S &kp SPACE &kp SPACE &kp SPACE>;
        };
        amx64_pxor: amx64_pxor {
            compatible = "zmk,behavior-macro";
            #binding-cells = <0>;
            wait-ms = <U_ANTMORPH_MACRO_WAIT>;
            tap-ms = <U_ANTMORPH_MACRO_TAP>;
            // [x]pxor    
            bindings = <&macro_tap &kp BSPC &kp P &kp X &kp O &kp R &kp SPACE &kp SPACE &kp SPACE &kp SPACE>;
        };
        amx64_pxor_xmm0_xmm0: amx64_pxor_xmm0_xmm0 {
            compatible = "zmk,behavior-macro";
            #binding-cells = <0>;
            wait-ms = <U_ANTMORPH_MACRO_WAIT>;
            tap-ms = <U_ANTMORPH_MACRO_TAP>;
            // [x]pxor    xmm0, xmm0
            bindings = <&macro_release &kp LGUI>, <&macro_tap &kp LGUI>, <&macro_tap &kp BSPC &kp P &kp X &kp O &kp R &kp SPACE &kp SPACE &kp SPACE &kp SPACE &kp X &kp M &kp M &kp N0 &kp COMMA &kp SPACE &kp X &kp M &kp M &kp N0>;
        };
        amx64_vxorpd: amx64_vxorpd {
            compatible = "zmk,behavior-macro";
            #binding-cells = <0>;
            wait-ms = <U_ANTMORPH_MACRO_WAIT>;
            tap-ms = <U_ANTMORPH_MACRO_TAP>;
            // [x]vxorpd  
            bindings = <&macro_tap &kp BSPC &kp V &kp X &kp O &kp R &kp P &kp D &kp SPACE &kp SPACE>;
        };
        amx64_vxorps: amx64_vxorps {
            compatible = "zmk,behavior-macro";
            #binding-cells = <0>;
            wait-ms = <U_ANTMORPH_MACRO_WAIT>;
            tap-ms = <U_ANTMORPH_MACRO_TAP>;
            // [x]vxorps  
            bindings = <&macro_release &kp RCTRL>, <&macro_tap &kp BSPC &kp V &kp X &kp O &kp R &kp P &kp S &kp SPACE &kp SPACE>;
        };
        // '0'
        amx64_ymm0: amx64_ymm0 {
            compatible = "zmk,behavior-macro";
            #binding-cells = <0>;
            wait-ms = <U_ANTMORPH_MACRO_WAIT>;
            tap-ms = <U_ANTMORPH_MACRO_TAP>;
            // [0]ymm0
            bindings = <&macro_tap &kp BSPC &kp Y &kp M &kp M &kp N0>;
        };
        amx64_ymm0_ymm0: amx64_ymm0_ymm0 {
            compatible = "zmk,behavior-macro";
            #binding-cells = <0>;
            wait-ms = <U_ANTMORPH_MACRO_WAIT>;
            tap-ms = <U_ANTMORPH_MACRO_TAP>;
            // [0]ymm0, ymm0
            bindings = <&macro_release &kp LCTRL>, <&macro_tap &kp BSPC &kp Y &kp M &kp M &kp N0 &kp COMMA &kp SPACE &kp Y &kp M &kp M &kp N0>;
        };
        amx64_xmm0: amx64_xmm0 {
            compatible = "zmk,behavior-macro";
            #binding-cells = <0>;
            wait-ms = <U_ANTMORPH_MACRO_WAIT>;
            tap-ms = <U_ANTMORPH_MACRO_TAP>;
            // [0]xmm0
            bindings = <&macro_tap &kp BSPC &kp X &kp M &kp M &kp N0>;
        };
        amx64_xmm0_xmm0: amx64_xmm0_xmm0 {
            compatible = "zmk,behavior-macro";
            #binding-cells = <0>;
            wait-ms = <U_ANTMORPH_MACRO_WAIT>;
            tap-ms = <U_ANTMORPH_MACRO_TAP>;
            // [0]xmm0, xmm0
            bindings = <&macro_release &kp LCTRL>, <&macro_tap &kp BSPC &kp X &kp M &kp M &kp N0 &kp COMMA &kp SPACE &kp X &kp M &kp M &kp N0>;
        };
        amx64_00000000: amx64_00000000 {
            compatible = "zmk,behavior-macro";
            #binding-cells = <0>;
            wait-ms = <U_ANTMORPH_MACRO_WAIT>;
            tap-ms = <U_ANTMORPH_MACRO_TAP>;
            // (0)0000000
            bindings = <&macro_tap &kp N0 &kp N0 &kp N0 &kp N0 &kp N0 &kp N0 &kp N0>;
        };
        amx64_000000000000000: amx64_000000000000000 {
            compatible = "zmk,behavior-macro";
            #binding-cells = <0>;
            wait-ms = <U_ANTMORPH_MACRO_WAIT>;
            tap-ms = <U_ANTMORPH_MACRO_TAP>;
            // (0)000000000000000
            bindings = <&macro_release &kp LCTRL>, <&macro_tap &kp N0 &kp N0 &kp N0 &kp N0 &kp N0 &kp N0 &kp N0 &kp N0 &kp N0 &kp N0 &kp N0 &kp N0 &kp N0 &kp N0 &kp N0>;
        };
        amx64_0000000000000001: amx64_0000000000000001 {
            compatible = "zmk,behavior-macro";
            #binding-cells = <0>;
            wait-ms = <U_ANTMORPH_MACRO_WAIT>;
            tap-ms = <U_ANTMORPH_MACRO_TAP>;
            // (0)0000000000000000000000000000000
            bindings = <&macro_release &kp LALT>, <&macro_tap &kp LALT>, <&macro_tap &kp N0 &kp N0 &kp N0 &kp N0 &kp N0 &kp N0 &kp N0 &kp N0 &kp N0 &kp N0 &kp N0 &kp N0 &kp N0 &kp N0 &kp N0 &kp N0 &kp N0 &kp N0 &kp N0 &kp N0 &kp N0 &kp N0 &kp N0 &kp N0 &kp N0 &kp N0 &kp N0 &kp N0 &kp N0 &kp N0 &kp N0>;
        };
        amx64_0000000000000002: amx64_0000000000000002 {
            compatible = "zmk,behavior-macro";
            #binding-cells = <0>;
            wait-ms = <U_ANTMORPH_MACRO_WAIT>;
            tap-ms = <U_ANTMORPH_MACRO_TAP>;
            // (0)000000000000000000000000000000000000000000000000000000000000000
            bindings = <&macro_release &kp LGUI>, <&macro_tap &kp LGUI>, <&macro_tap &kp N0 &kp N0 &kp N0 &kp N0 &kp N0 &kp N0 &kp N0 &kp N0 &kp N0 &kp N0 &kp N0 &kp N0 &kp N0 &kp N0 &kp N0 &kp N0 &kp N0 &kp N0 &kp N0 &kp N0 &kp N0 &kp N0 &kp N0 &kp N0 &kp N0 &kp N0 &kp N0 &kp N0 &kp N0 &kp N0 &kp N0 &kp N0 &kp N0 &kp N0 &kp N0 &kp N0 &kp N0 &kp N0 &kp N0 &kp N0 &kp N0 &kp N0 &kp N0 &kp N0 &kp N0 &kp N0 &kp N0 &kp N0 &kp N0 &kp N0 &kp N0 &kp N0 &kp N0 &kp N0 &kp N0 &kp N0 &kp N0 &kp N0 &kp N0 &kp N0 &kp N0 &kp N0 &kp N0>;
        };
        amx64_r10_r10: amx64_r10_r10 {
            compatible = "zmk,behavior-macro";
            #binding-cells = <0>;
            wait-ms = <U_ANTMORPH_MACRO_WAIT>;
            tap-ms = <U_ANTMORPH_MACRO_TAP>;
            // [0]r10, r10
            bindings = <&macro_tap &kp BSPC &kp R &kp N1 &kp N0 &kp COMMA &kp SPACE &kp R &kp N1 &kp N0>;
        };
        amx64_0xff: amx64_0xff {
            compatible = "zmk,behavior-macro";
            #binding-cells = <0>;
            wait-ms = <U_ANTMORPH_MACRO_WAIT>;
            tap-ms = <U_ANTMORPH_MACRO_TAP>;
            // (0)xff
            bindings = <&macro_tap &kp X &kp F &kp F>;
        };
        amx64_0xffff: amx64_0xffff {
            compatible = "zmk,behavior-macro";
            #binding-cells = <0>;
            wait-ms = <U_ANTMORPH_MACRO_WAIT>;
            tap-ms = <U_ANTMORPH_MACRO_TAP>;
            // (0)xffff
            bindings = <&macro_release &kp RCTRL>, <&macro_tap &kp X &kp F &kp F &kp F &kp F>;
        };
        amx64_0xffffffff: amx64_0xffffffff {
            compatible = "zmk,behavior-macro";
            #binding-cells = <0>;
            wait-ms = <U_ANTMORPH_MACRO_WAIT>;
            tap-ms = <U_ANTMORPH_MACRO_TAP>;
            // (0)xffffffff
            bindings = <&macro_release &kp RALT>, <&macro_tap &kp RALT>, <&macro_tap &kp X &kp F &kp F &kp F &kp F &kp F &kp F &kp F &kp F>;
        };
        amx64_0xfffffffffffff: amx64_0xfffffffffffff {
            compatible = "zmk,behavior-macro";
            #binding-cells = <0>;
            wait-ms = <U_ANTMORPH_MACRO_WAIT>;
            tap-ms = <U_ANTMORPH_MACRO_TAP>;
            // (0)xffffffffffffffff
            bindings = <&macro_release &kp RGUI>, <&macro_tap &kp RGUI>, <&macro_tap &kp X &kp F &kp F &kp F &kp F &kp F &kp F &kp F &kp F &kp F &kp F &kp F &kp F &kp F &kp F &kp F &kp F>;
        };
        amx64_0x00: amx64_0x00 {
            compatible = "zmk,behavior-macro";
            #binding-cells = <0>;
            wait-ms = <U_ANTMORPH_MACRO_WAIT>;
            tap-ms = <U_ANTMORPH_MACRO_TAP>;
            // (0)x00
            bindings = <&macro_tap &kp X &kp N0 &kp N0>;
        };
        amx64_0x0000: amx64_0x0000 {
            compatible = "zmk,behavior-macro";
            #binding-cells = <0>;
            wait-ms = <U_ANTMORPH_MACRO_WAIT>;
            tap-ms = <U_ANTMORPH_MACRO_TAP>;
            // (0)x0000
            bindings = <&macro_release &kp RCTRL>, <&macro_tap &kp X &kp N0 &kp N0 &kp N0 &kp N0>;
        };
        amx64_0x00000000: amx64_0x00000000 {
            compatible = "zmk,behavior-macro";
            #binding-cells = <0>;
            wait-ms = <U_ANTMORPH_MACRO_WAIT>;
            tap-ms = <U_ANTMORPH_MACRO_TAP>;
            // (0)x00000000
            bindings = <&macro_release &kp RALT>, <&macro_tap &kp RALT>, <&macro_tap &kp X &kp N0 &kp N0 &kp N0 &kp N0 &kp N0 &kp N0 &kp N0 &kp N0>;
        };
        amx64_0x0000000000000: amx64_0x0000000000000 {
            compatible = "zmk,behavior-macro";
            #binding-cells = <0>;
            wait-ms = <U_ANTMORPH_MACRO_WAIT>;
            tap-ms = <U_ANTMORPH_MACRO_TAP>;
            // (0)x0000000000000000
            bindings = <&macro_release &kp RGUI>, <&macro_tap &kp RGUI>, <&macro_tap &kp X &kp N0 &kp N0 &kp N0 &kp N0 &kp N0 &kp N0 &kp N0 &kp N0 &kp N0 &kp N0 &kp N0 &kp N0 &kp N0 &kp N0 &kp N0 &kp N0>;
        };
        // '1'
        amx64_ymm1: amx64_ymm1 {
            compatible = "zmk,behavior-macro";
            #binding-cells = <0>;
            wait-ms = <U_ANTMORPH_MACRO_WAIT>;
            tap-ms = <U_ANTMORPH_MACRO_TAP>;
            // [1]ymm1
            bindings = <&macro_tap &kp BSPC &kp Y &kp M &kp M &kp N1>;
        };
        amx64_ymm1_ymm1: amx64_ymm1_ymm1 {
            compatible = "zmk,behavior-macro";
            #binding-cells = <0>;
            wait-ms = <U_ANTMORPH_MACRO_WAIT>;
            tap-ms = <U_ANTMORPH_MACRO_TAP>;
            // [1]ymm1, ymm1
            bindings = <&macro_release &kp LCTRL>, <&macro_tap &kp BSPC &kp Y &kp M &kp M &kp N1 &kp COMMA &kp SPACE &kp Y &kp M &kp M &kp N1>;
        };
        amx64_xmm1: amx64_xmm1 {
            compatible = "zmk,behavior-macro";
            #binding-cells = <0>;
            wait-ms = <U_ANTMORPH_MACRO_WAIT>;
            tap-ms = <U_ANTMORPH_MACRO_TAP>;
            // [1]xmm1
            bindings = <&macro_tap &kp BSPC &kp X &kp M &kp M &kp N1>;
        };
        amx64_xmm1_xmm1: amx64_xmm1_xmm1 {
            compatible = "zmk,behavior-macro";
            #binding-cells = <0>;
            wait-ms = <U_ANTMORPH_MACRO_WAIT>;
            tap-ms = <U_ANTMORPH_MACRO_TAP>;
            // [1]xmm1, xmm1
            bindings = <&macro_release &kp LCTRL>, <&macro_tap &kp BSPC &kp X &kp M &kp M &kp N1 &kp COMMA &kp SPACE &kp X &kp M &kp M &kp N1>;
        };
        amx64_11111111: amx64_11111111 {
            compatible = "zmk,behavior-macro";
            #binding-cells = <0>;
            wait-ms = <U_ANTMORPH_MACRO_WAIT>;
            tap-ms = <U_ANTMORPH_MACRO_TAP>;
            // (1)1111111
            bindings = <&macro_tap &kp N1 &kp N1 &kp N1 &kp N1 &kp N1 &kp N1 &kp N1>;
        };
        amx64_111111111111111: amx64_111111111111111 {
            compatible = "zmk,behavior-macro";
            #binding-cells = <0>;
            wait-ms = <U_ANTMORPH_MACRO_WAIT>;
            tap-ms = <U_ANTMORPH_MACRO_TAP>;
            // (1)111111111111111
            bindings = <&macro_release &kp LCTRL>, <&macro_tap &kp N1 &kp N1 &kp N1 &kp N1 &kp N1 &kp N1 &kp N1 &kp N1 &kp N1 &kp N1 &kp N1 &kp N1 &kp N1 &kp N1 &kp N1>;
        };
        amx64_1111111111111111: amx64_1111111111111111 {
            compatible = "zmk,behavior-macro";
            #binding-cells = <0>;
            wait-ms = <U_ANTMORPH_MACRO_WAIT>;
            tap-ms = <U_ANTMORPH_MACRO_TAP>;
            // (1)1111111111111111111111111111111
            bindings = <&macro_release &kp LALT>, <&macro_tap &kp LALT>, <&macro_tap &kp N1 &kp N1 &kp N1 &kp N1 &kp N1 &kp N1 &kp N1 &kp N1 &kp N1 &kp N1 &kp N1 &kp N1 &kp N1 &kp N1 &kp N1 &kp N1 &kp N1 &kp N1 &kp N1 &kp N1 &kp N1 &kp N1 &kp N1 &kp N1 &kp N1 &kp N1 &kp N1 &kp N1 &kp N1 &kp N1 &kp N1>;
        };
        amx64_1111111111111112: amx64_1111111111111112 {
            compatible = "zmk,behavior-macro";
            #binding-cells = <0>;
            wait-ms = <U_ANTMORPH_MACRO_WAIT>;
            tap-ms = <U_ANTMORPH_MACRO_TAP>;
            // (1)111111111111111111111111111111111111111111111111111111111111111
            bindings = <&macro_release &kp LGUI>, <&macro_tap &kp LGUI>, <&macro_tap &kp N1 &kp N1 &kp N1 &kp N1 &kp N1 &kp N1 &kp N1 &kp N1 &kp N1 &kp N1 &kp N1 &kp N1 &kp N1 &kp N1 &kp N1 &kp N1 &kp N1 &kp N1 &kp N1 &kp N1 &kp N1 &kp N1 &kp N1 &kp N1 &kp N1 &kp N1 &kp N1 &kp N1 &kp N1 &kp N1 &kp N1 &kp N1 &kp N1 &kp N1 &kp N1 &kp N1 &kp N1 &kp N1 &kp N1 &kp N1 &kp N1 &kp N1 &kp N1 &kp N1 &kp N1 &kp N1 &kp N1 &kp N1 &kp N1 &kp N1 &kp N1 &kp N1 &kp N1 &kp N1 &kp N1 &kp N1 &kp N1 &kp N1 &kp N1 &kp N1 &kp N1 &kp N1 &kp N1>;
        };
        amx64_r11_r11: amx64_r11_r11 {
            compatible = "zmk,behavior-macro";
            #binding-cells = <0>;
            wait-ms = <U_ANTMORPH_MACRO_WAIT>;
            tap-ms = <U_ANTMORPH_MACRO_TAP>;
            // [1]r11, r11
            bindings = <&macro_tap &kp BSPC &kp R &kp N1 &kp N1 &kp COMMA &kp SPACE &kp R &kp N1 &kp N1>;
        };
        // '2'
        amx64_ymm2: amx64_ymm2 {
            compatible = "zmk,behavior-macro";
            #binding-cells = <0>;
            wait-ms = <U_ANTMORPH_MACRO_WAIT>;
            tap-ms = <U_ANTMORPH_MACRO_TAP>;
            // [2]ymm2
            bindings = <&macro_tap &kp BSPC &kp Y &kp M &kp M &kp N2>;
        };
        amx64_ymm2_ymm2: amx64_ymm2_ymm2 {
            compatible = "zmk,behavior-macro";
            #binding-cells = <0>;
            wait-ms = <U_ANTMORPH_MACRO_WAIT>;
            tap-ms = <U_ANTMORPH_MACRO_TAP>;
            // [2]ymm2, ymm2
            bindings = <&macro_release &kp LCTRL>, <&macro_tap &kp BSPC &kp Y &kp M &kp M &kp N2 &kp COMMA &kp SPACE &kp Y &kp M &kp M &kp N2>;
        };
        amx64_xmm2: amx64_xmm2 {
            compatible = "zmk,behavior-macro";
            #binding-cells = <0>;
            wait-ms = <U_ANTMORPH_MACRO_WAIT>;
            tap-ms = <U_ANTMORPH_MACRO_TAP>;
            // [2]xmm2
            bindings = <&macro_tap &kp BSPC &kp X &kp M &kp M &kp N2>;
        };
        amx64_xmm2_xmm2: amx64_xmm2_xmm2 {
            compatible = "zmk,behavior-macro";
            #binding-cells = <0>;
            wait-ms = <U_ANTMORPH_MACRO_WAIT>;
            tap-ms = <U_ANTMORPH_MACRO_TAP>;
            // [2]xmm2, xmm2
            bindings = <&macro_release &kp LCTRL>, <&macro_tap &kp BSPC &kp X &kp M &kp M &kp N2 &kp COMMA &kp SPACE &kp X &kp M &kp M &kp N2>;
        };
        amx64_r12_r12: amx64_r12_r12 {
            compatible = "zmk,behavior-macro";
            #binding-cells = <0>;
            wait-ms = <U_ANTMORPH_MACRO_WAIT>;
            tap-ms = <U_ANTMORPH_MACRO_TAP>;
            // [2]r12, r12
            bindings = <&macro_tap &kp BSPC &kp R &kp N1 &kp N2 &kp COMMA &kp SPACE &kp R &kp N1 &kp N2>;
        };
        // '3'
        amx64_ymm3: amx64_ymm3 {
            compatible = "zmk,behavior-macro";
            #binding-cells = <0>;
            wait-ms = <U_ANTMORPH_MACRO_WAIT>;
            tap-ms = <U_ANTMORPH_MACRO_TAP>;
            // [3]ymm3
            bindings = <&macro_tap &kp BSPC &kp Y &kp M &kp M &kp N3>;
        };
        amx64_ymm3_ymm3: amx64_ymm3_ymm3 {
            compatible = "zmk,behavior-macro";
            #binding-cells = <0>;
            wait-ms = <U_ANTMORPH_MACRO_WAIT>;
            tap-ms = <U_ANTMORPH_MACRO_TAP>;
            // [3]ymm3, ymm3
            bindings = <&macro_release &kp LCTRL>, <&macro_tap &kp BSPC &kp Y &kp M &kp M &kp N3 &kp COMMA &kp SPACE &kp Y &kp M &kp M &kp N3>;
        };
        amx64_xmm3: amx64_xmm3 {
            compatible = "zmk,behavior-macro";
            #binding-cells = <0>;
            wait-ms = <U_ANTMORPH_MACRO_WAIT>;
            tap-ms = <U_ANTMORPH_MACRO_TAP>;
            // [3]xmm3
            bindings = <&macro_tap &kp BSPC &kp X &kp M &kp M &kp N3>;
        };
        amx64_xmm3_xmm3: amx64_xmm3_xmm3 {
            compatible = "zmk,behavior-macro";
            #binding-cells = <0>;
            wait-ms = <U_ANTMORPH_MACRO_WAIT>;
            tap-ms = <U_ANTMORPH_MACRO_TAP>;
            // [3]xmm3, xmm3
            bindings = <&macro_release &kp LCTRL>, <&macro_tap &kp BSPC &kp X &kp M &kp M &kp N3 &kp COMMA &kp SPACE &kp X &kp M &kp M &kp N3>;
        };
        amx64_r13_r13: amx64_r13_r13 {
            compatible = "zmk,behavior-macro";
            #binding-cells = <0>;
            wait-ms = <U_ANTMORPH_MACRO_WAIT>;
            tap-ms = <U_ANTMORPH_MACRO_TAP>;
            // [3]r13, r13
            bindings = <&macro_tap &kp BSPC &kp R &kp N1 &kp N3 &kp COMMA &kp SPACE &kp R &kp N1 &kp N3>;
        };
        // '4'
        amx64_ymm4: amx64_ymm4 {
            compatible = "zmk,behavior-macro";
            #binding-cells = <0>;
            wait-ms = <U_ANTMORPH_MACRO_WAIT>;
            tap-ms = <U_ANTMORPH_MACRO_TAP>;
            // [4]ymm4
            bindings = <&macro_tap &kp BSPC &kp Y &kp M &kp M &kp N4>;
        };
        amx64_ymm4_ymm4: amx64_ymm4_ymm4 {
            compatible = "zmk,behavior-macro";
            #binding-cells = <0>;
            wait-ms = <U_ANTMORPH_MACRO_WAIT>;
            tap-ms = <U_ANTMORPH_MACRO_TAP>;
            // [4]ymm4, ymm4
            bindings = <&macro_release &kp LCTRL>, <&macro_tap &kp BSPC &kp Y &kp M &kp M &kp N4 &kp COMMA &kp SPACE &kp Y &kp M &kp M &kp N4>;
        };
        amx64_xmm4: amx64_xmm4 {
            compatible = "zmk,behavior-macro";
            #binding-cells = <0>;
            wait-ms = <U_ANTMORPH_MACRO_WAIT>;
            tap-ms = <U_ANTMORPH_MACRO_TAP>;
            // [4]xmm4
            bindings = <&macro_tap &kp BSPC &kp X &kp M &kp M &kp N4>;
        };
        amx64_xmm4_xmm4: amx64_xmm4_xmm4 {
            compatible = "zmk,behavior-macro";
            #binding-cells = <0>;
            wait-ms = <U_ANTMORPH_MACRO_WAIT>;
            tap-ms = <U_ANTMORPH_MACRO_TAP>;
            // [4]xmm4, xmm4
            bindings = <&macro_release &kp LCTRL>, <&macro_tap &kp BSPC &kp X &kp M &kp M &kp N4 &kp COMMA &kp SPACE &kp X &kp M &kp M &kp N4>;
        };
        amx64_r14_r14: amx64_r14_r14 {
            compatible = "zmk,behavior-macro";
            #binding-cells = <0>;
            wait-ms = <U_ANTMORPH_MACRO_WAIT>;
            tap-ms = <U_ANTMORPH_MACRO_TAP>;
            // [4]r14, r14
            bindings = <&macro_tap &kp BSPC &kp R &kp N1 &kp N4 &kp COMMA &kp SPACE &kp R &kp N1 &kp N4>;
        };
        // '5'
        amx64_ymm5: amx64_ymm5 {
            compatible = "zmk,behavior-macro";
            #binding-cells = <0>;
            wait-ms = <U_ANTMORPH_MACRO_WAIT>;
            tap-ms = <U_ANTMORPH_MACRO_TAP>;
            // [5]ymm5
            bindings = <&macro_tap &kp BSPC &kp Y &kp M &kp M &kp N5>;
        };
        amx64_ymm5_ymm5: amx64_ymm5_ymm5 {
            compatible = "zmk,behavior-macro";
            #binding-cells = <0>;
            wait-ms = <U_ANTMORPH_MACRO_WAIT>;
            tap-ms = <U_ANTMORPH_MACRO_TAP>;
            // [5]ymm5, ymm5
            bindings = <&macro_release &kp LCTRL>, <&macro_tap &kp BSPC &kp Y &kp M &kp M &kp N5 &kp COMMA &kp SPACE &kp Y &kp M &kp M &kp N5>;
        };
        amx64_xmm5: amx64_xmm5 {
            compatible = "zmk,behavior-macro";
            #binding-cells = <0>;
            wait-ms = <U_ANTMORPH_MACRO_WAIT>;
            tap-ms = <U_ANTMORPH_MACRO_TAP>;
            // [5]xmm5
            bindings = <&macro_tap &kp BSPC &kp X &kp M &kp M &kp N5>;
        };
        amx64_xmm5_xmm5: amx64_xmm5_xmm5 {
            compatible = "zmk,behavior-macro";
            #binding-cells = <0>;
            wait-ms = <U_ANTMORPH_MACRO_WAIT>;
            tap-ms = <U_ANTMORPH_MACRO_TAP>;
            // [5]xmm5, xmm5
            bindings = <&macro_release &kp LCTRL>, <&macro_tap &kp BSPC &kp X &kp M &kp M &kp N5 &kp COMMA &kp SPACE &kp X &kp M &kp M &kp N5>;
        };
        amx64_r15_r15: amx64_r15_r15 {
            compatible = "zmk,behavior-macro";
            #binding-cells = <0>;
            wait-ms = <U_ANTMORPH_MACRO_WAIT>;
            tap-ms = <U_ANTMORPH_MACRO_TAP>;
            // [5]r15, r15
            bindings = <&macro_tap &kp BSPC &kp R &kp N1 &kp N5 &kp COMMA &kp SPACE &kp R &kp N1 &kp N5>;
        };
        // '6'
        amx64_ymm6: amx64_ymm6 {
            compatible = "zmk,behavior-macro";
            #binding-cells = <0>;
            wait-ms = <U_ANTMORPH_MACRO_WAIT>;
            tap-ms = <U_ANTMORPH_MACRO_TAP>;
            // [6]ymm6
            bindings = <&macro_tap &kp BSPC &kp Y &kp M &kp M &kp N6>;
        };
        amx64_ymm6_ymm6: amx64_ymm6_ymm6 {
            compatible = "zmk,behavior-macro";
            #binding-cells = <0>;
            wait-ms = <U_ANTMORPH_MACRO_WAIT>;
            tap-ms = <U_ANTMORPH_MACRO_TAP>;
            // [6]ymm6, ymm6
            bindings = <&macro_release &kp LCTRL>, <&macro_tap &kp BSPC &kp Y &kp M &kp M &kp N6 &kp COMMA &kp SPACE &kp Y &kp M &kp M &kp N6>;
        };
        amx64_xmm6: amx64_xmm6 {
            compatible = "zmk,behavior-macro";
            #binding-cells = <0>;
            wait-ms = <U_ANTMORPH_MACRO_WAIT>;
            tap-ms = <U_ANTMORPH_MACRO_TAP>;
            // [6]xmm6
            bindings = <&macro_tap &kp BSPC &kp X &kp M &kp M &kp N6>;
        };
        amx64_xmm6_xmm6: amx64_xmm6_xmm6 {
            compatible = "zmk,behavior-macro";
            #binding-cells = <0>;
            wait-ms = <U_ANTMORPH_MACRO_WAIT>;
            tap-ms = <U_ANTMORPH_MACRO_TAP>;
            // [6]xmm6, xmm6
            bindings = <&macro_release &kp LCTRL>, <&macro_tap &kp BSPC &kp X &kp M &kp M &kp N6 &kp COMMA &kp SPACE &kp X &kp M &kp M &kp N6>;
        };
        // '7'
        amx64_ymm7: amx64_ymm7 {
            compatible = "zmk,behavior-macro";
            #binding-cells = <0>;
            wait-ms = <U_ANTMORPH_MACRO_WAIT>;
            tap-ms = <U_ANTMORPH_MACRO_TAP>;
            // [7]ymm7
            bindings = <&macro_tap &kp BSPC &kp Y &kp M &kp M &kp N7>;
        };
        amx64_ymm7_ymm7: amx64_ymm7_ymm7 {
            compatible = "zmk,behavior-macro";
            #binding-cells = <0>;
            wait-ms = <U_ANTMORPH_MACRO_WAIT>;
            tap-ms = <U_ANTMORPH_MACRO_TAP>;
            // [7]ymm7, ymm7
            bindings = <&macro_release &kp LCTRL>, <&macro_tap &kp BSPC &kp Y &kp M &kp M &kp N7 &kp COMMA &kp SPACE &kp Y &kp M &kp M &kp N7>;
        };
        amx64_xmm7: amx64_xmm7 {
            compatible = "zmk,behavior-macro";
            #binding-cells = <0>;
            wait-ms = <U_ANTMORPH_MACRO_WAIT>;
            tap-ms = <U_ANTMORPH_MACRO_TAP>;
            // [7]xmm7
            bindings = <&macro_tap &kp BSPC &kp X &kp M &kp M &kp N7>;
        };
        amx64_xmm7_xmm7: amx64_xmm7_xmm7 {
            compatible = "zmk,behavior-macro";
            #binding-cells = <0>;
            wait-ms = <U_ANTMORPH_MACRO_WAIT>;
            tap-ms = <U_ANTMORPH_MACRO_TAP>;
            // [7]xmm7, xmm7
            bindings = <&macro_release &kp LCTRL>, <&macro_tap &kp BSPC &kp X &kp M &kp M &kp N7 &kp COMMA &kp SPACE &kp X &kp M &kp M &kp N7>;
        };
        // '8'
        amx64_ymm8: amx64_ymm8 {
            compatible = "zmk,behavior-macro";
            #binding-cells = <0>;
            wait-ms = <U_ANTMORPH_MACRO_WAIT>;
            tap-ms = <U_ANTMORPH_MACRO_TAP>;
            // [8]ymm8
            bindings = <&macro_tap &kp BSPC &kp Y &kp M &kp M &kp N8>;
        };
        amx64_ymm8_ymm8: amx64_ymm8_ymm8 {
            compatible = "zmk,behavior-macro";
            #binding-cells = <0>;
            wait-ms = <U_ANTMORPH_MACRO_WAIT>;
            tap-ms = <U_ANTMORPH_MACRO_TAP>;
            // [8]ymm8, ymm8
            bindings = <&macro_release &kp LCTRL>, <&macro_tap &kp BSPC &kp Y &kp M &kp M &kp N8 &kp COMMA &kp SPACE &kp Y &kp M &kp M &kp N8>;
        };
        amx64_xmm8: amx64_xmm8 {
            compatible = "zmk,behavior-macro";
            #binding-cells = <0>;
            wait-ms = <U_ANTMORPH_MACRO_WAIT>;
            tap-ms = <U_ANTMORPH_MACRO_TAP>;
            // [8]xmm8
            bindings = <&macro_tap &kp BSPC &kp X &kp M &kp M &kp N8>;
        };
        amx64_xmm8_xmm8: amx64_xmm8_xmm8 {
            compatible = "zmk,behavior-macro";
            #binding-cells = <0>;
            wait-ms = <U_ANTMORPH_MACRO_WAIT>;
            tap-ms = <U_ANTMORPH_MACRO_TAP>;
            // [8]xmm8, xmm8
            bindings = <&macro_release &kp LCTRL>, <&macro_tap &kp BSPC &kp X &kp M &kp M &kp N8 &kp COMMA &kp SPACE &kp X &kp M &kp M &kp N8>;
        };
        amx64_r8_r8: amx64_r8_r8 {
            compatible = "zmk,behavior-macro";
            #binding-cells = <0>;
            wait-ms = <U_ANTMORPH_MACRO_WAIT>;
            tap-ms = <U_ANTMORPH_MACRO_TAP>;
            // [8]r8, r8
            bindings = <&macro_tap &kp BSPC &kp R &kp N8 &kp COMMA &kp SPACE &kp R &kp N8>;
        };
        // '9'
        amx64_ymm9: amx64_ymm9 {
            compatible = "zmk,behavior-macro";
            #binding-cells = <0>;
            wait-ms = <U_ANTMORPH_MACRO_WAIT>;
            tap-ms = <U_ANTMORPH_MACRO_TAP>;
            // [9]ymm9
            bindings = <&macro_tap &kp BSPC &kp Y &kp M &kp M &kp N9>;
        };
        amx64_ymm9_ymm9: amx64_ymm9_ymm9 {
            compatible = "zmk,behavior-macro";
            #binding-cells = <0>;
            wait-ms = <U_ANTMORPH_MACRO_WAIT>;
            tap-ms = <U_ANTMORPH_MACRO_TAP>;
            // [9]ymm9, ymm9
            bindings = <&macro_release &kp LCTRL>, <&macro_tap &kp BSPC &kp Y &kp M &kp M &kp N9 &kp COMMA &kp SPACE &kp Y &kp M &kp M &kp N9>;
        };
        amx64_xmm9: amx64_xmm9 {
            compatible = "zmk,behavior-macro";
            #binding-cells = <0>;
            wait-ms = <U_ANTMORPH_MACRO_WAIT>;
            tap-ms = <U_ANTMORPH_MACRO_TAP>;
            // [9]xmm9
            bindings = <&macro_tap &kp BSPC &kp X &kp M &kp M &kp N9>;
        };
        amx64_xmm9_xmm9: amx64_xmm9_xmm9 {
            compatible = "zmk,behavior-macro";
            #binding-cells = <0>;
            wait-ms = <U_ANTMORPH_MACRO_WAIT>;
            tap-ms = <U_ANTMORPH_MACRO_TAP>;
            // [9]xmm9, xmm9
            bindings = <&macro_release &kp LCTRL>, <&macro_tap &kp BSPC &kp X &kp M &kp M &kp N9 &kp COMMA &kp SPACE &kp X &kp M &kp M &kp N9>;
        };
        amx64_r9_r9: amx64_r9_r9 {
            compatible = "zmk,behavior-macro";
            #binding-cells = <0>;
            wait-ms = <U_ANTMORPH_MACRO_WAIT>;
            tap-ms = <U_ANTMORPH_MACRO_TAP>;
            // [9]r9, r9
            bindings = <&macro_tap &kp BSPC &kp R &kp N9 &kp COMMA &kp SPACE &kp R &kp N9>;
        };
        // ','
        amx64_100: amx64_100 {
            compatible = "zmk,behavior-macro";
            #binding-cells = <0>;
            wait-ms = <U_ANTMORPH_MACRO_WAIT>;
            tap-ms = <U_ANTMORPH_MACRO_TAP>;
            // (,)10,0
            bindings = <&macro_tap &kp N1 &kp N0 &kp COMMA &kp N0>;
        };
        amx64_10100: amx64_10100 {
            compatible = "zmk,behavior-macro";
            #binding-cells = <0>;
            wait-ms = <U_ANTMORPH_MACRO_WAIT>;
            tap-ms = <U_ANTMORPH_MACRO_TAP>;
            // (,)10,10,0
            bindings = <&macro_release &kp RCTRL>, <&macro_tap &kp N1 &kp N0 &kp COMMA &kp N1 &kp N0 &kp COMMA &kp N0>;
        };
        // '''
        amx64_1001: amx64_1001 {
            compatible = "zmk,behavior-macro";
            #binding-cells = <0>;
            wait-ms = <U_ANTMORPH_MACRO_WAIT>;
            tap-ms = <U_ANTMORPH_MACRO_TAP>;
            // ('),10,0
            bindings = <&macro_tap &kp COMMA &kp N1 &kp N0 &kp COMMA &kp N0>;
        };
        amx64_101001: amx64_101001 {
            compatible = "zmk,behavior-macro";
            #binding-cells = <0>;
            wait-ms = <U_ANTMORPH_MACRO_WAIT>;
            tap-ms = <U_ANTMORPH_MACRO_TAP>;
            // ('),10,10,0
            bindings = <&macro_release &kp RCTRL>, <&macro_tap &kp COMMA &kp N1 &kp N0 &kp COMMA &kp N1 &kp N0 &kp COMMA &kp N0>;
        };
        amx64_0: amx64_0 {
            compatible = "zmk,behavior-macro";
            #binding-cells = <0>;
            wait-ms = <U_ANTMORPH_MACRO_WAIT>;
            tap-ms = <U_ANTMORPH_MACRO_TAP>;
            // ('),0
            bindings = <&macro_tap &kp COMMA &kp N0>;
        };
        amx64_9: amx64_9 {
            compatible = "zmk,behavior-macro";
            #binding-cells = <0>;
            wait-ms = <U_ANTMORPH_MACRO_WAIT>;
            tap-ms = <U_ANTMORPH_MACRO_TAP>;
            // ('),9
            bindings = <&macro_tap &kp COMMA &kp N9>;
        };
        // '%'
        amx64_macro: amx64_macro {
            compatible = "zmk,behavior-macro";
            #binding-cells = <0>;
            wait-ms = <U_ANTMORPH_MACRO_WAIT>;
            tap-ms = <U_ANTMORPH_MACRO_TAP>;
            // (%)macro 
            bindings = <&macro_tap &kp M &kp A &kp C &kp R &kp O &kp SPACE>;
        };
        amx64_unmacro: amx64_unmacro {
            compatible = "zmk,behavior-macro";
            #binding-cells = <0>;
            wait-ms = <U_ANTMORPH_MACRO_WAIT>;
            tap-ms = <U_ANTMORPH_MACRO_TAP>;
            // (%)unmacro 
            bindings = <&macro_release &kp LCTRL>, <&macro_tap &kp U &kp N &kp M &kp A &kp C &kp R &kp O &kp SPACE>;
        };
        amx64_define: amx64_define {
            compatible = "zmk,behavior-macro";
            #binding-cells = <0>;
            wait-ms = <U_ANTMORPH_MACRO_WAIT>;
            tap-ms = <U_ANTMORPH_MACRO_TAP>;
            // (%)define 
            bindings = <&macro_tap &kp D &kp E &kp F &kp I &kp N &kp E &kp SPACE>;
        };
        amx64_undef: amx64_undef {
            compatible = "zmk,behavior-macro";
            #binding-cells = <0>;
            wait-ms = <U_ANTMORPH_MACRO_WAIT>;
            tap-ms = <U_ANTMORPH_MACRO_TAP>;
            // (%)undef 
            bindings = <&macro_release &kp LCTRL>, <&macro_tap &kp U &kp N &kp D &kp E &kp F &kp SPACE>;
        };
        amx64_xdefine: amx64_xdefine {
            compatible = "zmk,behavior-macro";
            #binding-cells = <0>;
            wait-ms = <U_ANTMORPH_MACRO_WAIT>;
            tap-ms = <U_ANTMORPH_MACRO_TAP>;
            // (%)xdefine 
            bindings = <&macro_release &kp LALT>, <&macro_tap &kp LALT>, <&macro_tap &kp X &kp D &kp E &kp F &kp I &kp N &kp E &kp SPACE>;
        };
        amx64_endmacro: amx64_endmacro {
            compatible = "zmk,behavior-macro";
            #binding-cells = <0>;
            wait-ms = <U_ANTMORPH_MACRO_WAIT>;
            tap-ms = <U_ANTMORPH_MACRO_TAP>;
            // (%)endmacro
            bindings = <&macro_tap &kp E &kp N &kp D &kp M &kp A &kp C &kp R &kp O>;
        };
        amx64_include: amx64_include {
            compatible = "zmk,behavior-macro";
            #binding-cells = <0>;
            wait-ms = <U_ANTMORPH_MACRO_WAIT>;
            tap-ms = <U_ANTMORPH_MACRO_TAP>;
            // (%)include ""←
            bindings = <&macro_tap &kp I &kp N &kp C &kp L &kp U &kp D &kp E &kp SPACE &kp DQT &kp DQT &kp LEFT>;
        };
        amx64_if: amx64_if {
            compatible = "zmk,behavior-macro";
            #binding-cells = <0>;
            wait-ms = <U_ANTMORPH_MACRO_WAIT>;
            tap-ms = <U_ANTMORPH_MACRO_TAP>;
            // (%)if
            bindings = <&macro_tap &kp I &kp F>;
        };
        amx64_elif: amx64_elif {
            compatible = "zmk,behavior-macro";
            #binding-cells = <0>;
            wait-ms = <U_ANTMORPH_MACRO_WAIT>;
            tap-ms = <U_ANTMORPH_MACRO_TAP>;
            // (%)elif
            bindings = <&macro_release &kp RCTRL>, <&macro_tap &kp E &kp L &kp I &kp F>;
        };
        amx64_else: amx64_else {
            compatible = "zmk,behavior-macro";
            #binding-cells = <0>;
            wait-ms = <U_ANTMORPH_MACRO_WAIT>;
            tap-ms = <U_ANTMORPH_MACRO_TAP>;
            // (%)else
            bindings = <&macro_release &kp RALT>, <&macro_tap &kp RALT>, <&macro_tap &kp E &kp L &kp S &kp E>;
        };
        amx64_endif: amx64_endif {
            compatible = "zmk,behavior-macro";
            #binding-cells = <0>;
            wait-ms = <U_ANTMORPH_MACRO_WAIT>;
            tap-ms = <U_ANTMORPH_MACRO_TAP>;
            // (%)endif
            bindings = <&macro_tap &kp E &kp N &kp D &kp I &kp F>;
        };
        // '@'
        amx64_rep: amx64_rep {
            compatible = "zmk,behavior-macro";
            #binding-cells = <0>;
            wait-ms = <U_ANTMORPH_MACRO_WAIT>;
            tap-ms = <U_ANTMORPH_MACRO_TAP>;
            // [@]%rep 
            bindings = <&macro_tap &kp BSPC &kp PRCNT &kp R &kp E &kp P &kp SPACE>;
        };
        amx64_exitrep: amx64_exitrep {
            compatible = "zmk,behavior-macro";
            #binding-cells = <0>;
            wait-ms = <U_ANTMORPH_MACRO_WAIT>;
            tap-ms = <U_ANTMORPH_MACRO_TAP>;
            // [@]%exitrep
            bindings = <&macro_release &kp LCTRL>, <&macro_tap &kp BSPC &kp PRCNT &kp E &kp X &kp I &kp T &kp R &kp E &kp P>;
        };
        amx64_endrep: amx64_endrep {
            compatible = "zmk,behavior-macro";
            #binding-cells = <0>;
            wait-ms = <U_ANTMORPH_MACRO_WAIT>;
            tap-ms = <U_ANTMORPH_MACRO_TAP>;
            // [@]%endrep
            bindings = <&macro_tap &kp BSPC &kp PRCNT &kp E &kp N &kp D &kp R &kp E &kp P>;
        };
        // '='
        amx64_assign: amx64_assign {
            compatible = "zmk,behavior-macro";
            #binding-cells = <0>;
            wait-ms = <U_ANTMORPH_MACRO_WAIT>;
            tap-ms = <U_ANTMORPH_MACRO_TAP>;
            // [=]%assign 
            bindings = <&macro_tap &kp BSPC &kp PRCNT &kp A &kp S &kp S &kp I &kp G &kp N &kp SPACE>;
        };
        // ' '
        amx64_x64_v11: amx64_x64_v11 {
            compatible = "zmk,behavior-macro";
            #binding-cells = <0>;
            wait-ms = <U_ANTMORPH_MACRO_WAIT>;
            tap-ms = <U_ANTMORPH_MACRO_TAP>;
            // [ ]x64 v1.1
            bindings = <&macro_tap &kp BSPC &kp X &kp N6 &kp N4 &kp SPACE &kp V &kp N1 &kp DOT &kp N1>;
        };
    };
};
